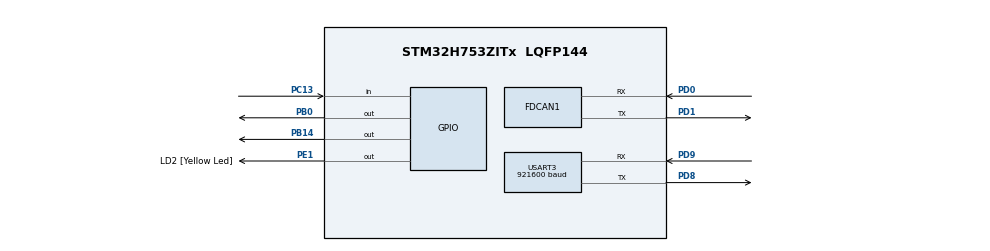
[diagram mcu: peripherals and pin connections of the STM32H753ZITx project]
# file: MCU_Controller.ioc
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CORTEX_M7.CPU_DCache=Disabled
CORTEX_M7.CPU_ICache=Disabled
CORTEX_M7.MPU_Control=MPU_PRIVILEGED_DEFAULT
CORTEX_M7.default_mode_Activation=1
Dma.Request0=USART3_RX
Dma.Request1=USART3_TX
Dma.USART3_RX.0.Direction=DMA_PERIPH_TO_MEMORY
Dma.USART3_RX.0.EventEnable=DISABLE
Dma.USART3_RX.0.FIFOMode=DMA_FIFOMODE_DISABLE
Dma.USART3_RX.0.Instance=DMA1_Stream0
Dma.USART3_RX.0.MemDataAlignment=DMA_MDATAALIGN_BYTE
Dma.USART3_RX.0.MemInc=DMA_MINC_ENABLE
Dma.USART3_RX.0.Mode=DMA_NORMAL
Dma.USART3_RX.0.PeriphDataAlignment=DMA_PDATAALIGN_BYTE
Dma.USART3_RX.0.PeriphInc=DMA_PINC_DISABLE
Dma.USART3_RX.0.Polarity=HAL_DMAMUX_REQ_GEN_RISING
Dma.USART3_RX.0.Priority=DMA_PRIORITY_LOW
Dma.USART3_RX.0.RequestNumber=1
Dma.USART3_RX.0.SignalID=NONE
Dma.USART3_RX.0.SyncEnable=DISABLE
Dma.USART3_RX.0.SyncPolarity=HAL_DMAMUX_SYNC_NO_EVENT
Dma.USART3_RX.0.SyncRequestNumber=1
Dma.USART3_RX.0.SyncSignalID=NONE
Dma.USART3_TX.1.Direction=DMA_MEMORY_TO_PERIPH
Dma.USART3_TX.1.EventEnable=DISABLE
Dma.USART3_TX.1.FIFOMode=DMA_FIFOMODE_DISABLE
Dma.USART3_TX.1.Instance=DMA1_Stream1
Dma.USART3_TX.1.MemDataAlignment=DMA_MDATAALIGN_BYTE
Dma.USART3_TX.1.MemInc=DMA_MINC_ENABLE
Dma.USART3_TX.1.Mode=DMA_NORMAL
Dma.USART3_TX.1.PeriphDataAlignment=DMA_PDATAALIGN_BYTE
Dma.USART3_TX.1.PeriphInc=DMA_PINC_DISABLE
Dma.USART3_TX.1.Polarity=HAL_DMAMUX_REQ_GEN_RISING
Dma.USART3_TX.1.Priority=DMA_PRIORITY_LOW
Dma.USART3_TX.1.RequestNumber=1
Dma.USART3_TX.1.SignalID=NONE
Dma.USART3_TX.1.SyncEnable=DISABLE
Dma.USART3_TX.1.SyncPolarity=HAL_DMAMUX_SYNC_NO_EVENT
Dma.USART3_TX.1.SyncRequestNumber=1
Dma.USART3_TX.1.SyncSignalID=NONE
FDCAN1.AutoRetransmission=ENABLE
FDCAN1.CalculateBaudRateNominal=1000000
FDCAN1.CalculateTimeBitNominal=1000
FDCAN1.CalculateTimeQuantumNominal=25.0
FDCAN1.DataSyncJumpWidth=4
FDCAN1.DataTimeSeg1=5
FDCAN1.DataTimeSeg2=4
FDCAN1.NominalPrescaler=1
FDCAN1.NominalSyncJumpWidth=8
FDCAN1.NominalTimeSeg1=31
FDCAN1.NominalTimeSeg2=8
FDCAN1.RxBuffersNbr=4
FDCAN1.RxFifo0ElmtsNbr=64
FDCAN1.TxBuffersNbr=16
FDCAN1.TxEventsNbr=16
FDCAN1.TxFifoQueueElmtsNbr=32
FDCAN1.TxFifoQueueMode=FDCAN_TX_FIFO_OPERATION
FREERTOS.Tasks01=Control,40,1024,ControlTask,Default,NULL,Dynamic,NULL,NULL;DataLogging,8,2048,DataLoggingTask,Default,NULL,Dynamic,NULL,NULL
FREERTOS.configQUEUE_REGISTRY_SIZE=8
FREERTOS.configTICK_RATE_HZ=500
FREERTOS.configUSE_NEWLIB_REENTRANT=1
Mcu.Family=STM32H7
Mcu.Name=STM32H753ZITx
Mcu.Package=LQFP144
NUCLEO-H753ZI.BUTTON=1
NUCLEO-H753ZI.LD1=true
NUCLEO-H753ZI.LD2=true
NUCLEO-H753ZI.LD3=true
NUCLEO-H753ZI.VCP=false
NVIC.DMA1_Stream0_IRQn=true\:8\:0\:true\:false\:true\:true\:false\:true\:true
NVIC.DMA1_Stream1_IRQn=true\:8\:0\:true\:false\:true\:true\:false\:true\:true
NVIC.EXTI15_10_IRQn=true\:5\:0\:false\:false\:true\:true\:false\:true\:true
NVIC.FDCAN1_IT0_IRQn=true\:6\:0\:true\:false\:true\:true\:true\:true\:true
NVIC.FDCAN1_IT1_IRQn=true\:6\:0\:true\:false\:true\:true\:true\:true\:true
NVIC.PriorityGroup=NVIC_PRIORITYGROUP_4
NVIC.TIM7_IRQn=true\:15\:0\:false\:false\:true\:false\:false\:true\:true
NVIC.TimeBase=TIM7_IRQn
NVIC.TimeBaseIP=TIM7
NVIC.USART3_IRQn=true\:8\:0\:true\:false\:true\:true\:true\:true\:true
PA13\ (JTMS/SWDIO).Signal=DEBUG_JTMS-SWDIO
PA14\ (JTCK/SWCLK).Signal=DEBUG_JTCK-SWCLK
PB0.Signal=GPIO_Output
PB14.Signal=GPIO_Output
PC13.Signal=GPIO_Input
PC14-OSC32_IN\ (OSC32_IN).Signal=RCC_OSC32_IN
PC15-OSC32_OUT\ (OSC32_OUT).Signal=RCC_OSC32_OUT
PD0.GPIO_Speed=GPIO_SPEED_FREQ_HIGH
PD0.Mode=FDCAN_Activate
PD0.Signal=FDCAN1_RX
PD1.GPIO_Speed=GPIO_SPEED_FREQ_HIGH
PD1.Mode=FDCAN_Activate
PD1.Signal=FDCAN1_TX
PD8.Mode=Asynchronous
PD8.Signal=USART3_TX
PD9.Mode=Asynchronous
PD9.Signal=USART3_RX
PE1.GPIO_Label=LD2 [Yellow Led]
PE1.Signal=GPIO_Output
PH0-OSC_IN\ (PH0).Mode=HSE-External-Oscillator
PH0-OSC_IN\ (PH0).Signal=RCC_OSC_IN
PH1-OSC_OUT\ (PH1).Mode=HSE-External-Oscillator
PH1-OSC_OUT\ (PH1).Signal=RCC_OSC_OUT
ProjectManager.HeapSize=0x200
ProjectManager.StackSize=0x400
ProjectManager.TargetToolchain=STM32CubeIDE
RCC.ADCFreq_Value=400000000
RCC.APB1Freq_Value=100000000
RCC.APB2Freq_Value=100000000
RCC.APB3Freq_Value=100000000
RCC.APB4Freq_Value=100000000
RCC.CortexFreq_Value=400000000
RCC.D1PPRE=RCC_APB3_DIV2
RCC.D2PPRE1=RCC_APB1_DIV2
RCC.D2PPRE2=RCC_APB2_DIV2
RCC.D3PPRE=RCC_APB4_DIV2
RCC.DIVM1=1
RCC.DIVM2=1
RCC.DIVN1=100
RCC.DIVN2=100
RCC.DIVQ1=16
RCC.DIVQ2=20
RCC.FDCANCLockSelection=RCC_FDCANCLKSOURCE_PLL2
RCC.HCLKFreq_Value=200000000
RCC.HPRE=RCC_HCLK_DIV2
RCC.HSE_VALUE=8000000
RCC.PLLFRACN=0
RCC.PLLSourceVirtual=RCC_PLLSOURCE_HSE
RCC.PWR_Regulator_Voltage_Scale=PWR_REGULATOR_VOLTAGE_SCALE1
RCC.SYSCLKFreq_VALUE=400000000
RCC.SYSCLKSource=RCC_SYSCLKSOURCE_PLLCLK
RCC.USBFreq_Value=50000000
STMicroelectronics.FP-SNS-STAIOTCFT.1.0.0.MathOoLibCcCMSISJjDSPJjInclude=true
STMicroelectronics.FP-SNS-STAIOTCFT.1.0.0.MathOoLibCcCMSISJjDSPJjLib=true
USART3.BaudRate=921600
USART3.FIFOMode=FIFOMODE_ENABLE
USART3.RXFIFOThreshold=RXFIFO_THRESHOLD_HALFFULL
USART3.TXFIFOThreshold=TXFIFO_THRESHOLD_HALFFULL
USART3.VirtualMode-Asynchronous=VM_ASYNC
VP_FREERTOS_VS_CMSIS_V2.Mode=CMSIS_V2
VP_MEMORYMAP_VS_MEMORYMAP.Mode=CurAppReg
VP_NUCLEO-H753ZI_VS_BSP_COMMON.Mode=COMMON
VP_STMicroelectronics.FP-SNS-STAIOTCFT_VS_CMSISJjMathOoLib_1.0.0_1.0.0.Mode=CMSISJjMathOoLib
VP_SYS_VS_tim7.Mode=TIM7
board=NUCLEO-H753ZI

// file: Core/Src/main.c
/* USER CODE BEGIN Header */
/**
  ******************************************************************************
  * @file           : main.c
  * @brief          : Main program body
  ******************************************************************************
  * @attention
  *
  * Copyright (c) 2025 STMicroelectronics.
  * All rights reserved.
  *
  * This software is licensed under terms that can be found in the LICENSE file
  * in the root directory of this software component.
  * If no LICENSE file comes with this software, it is provided AS-IS.
  *
  ******************************************************************************
  */
/* USER CODE END Header */
#include "main.h"
#include "cmsis_os.h"

/* USER CODE BEGIN Includes */
#include <stdio.h>
#include "FreeRTOS.h"	// Real Time task 세팅을 위해 사용
#include "arm_math.h"	// 선형 대수 연산을 위해 사용
#include "queue.h"		// CAN 통신 수신을 위해 사용
#include "task.h"		// Real Time task 세팅을 위해 사용
#include <string.h>
#include <stdlib.h>   // strtof
#include <errno.h>
#include <stdbool.h>
/* USER CODE END Includes */

/* USER CODE BEGIN PTD */
FDCAN_TxHeaderTypeDef TxHeader;
FDCAN_RxHeaderTypeDef RxHeader;
/* USER CODE END PTD */

FDCAN_HandleTypeDef hfdcan1;

UART_HandleTypeDef huart3;
DMA_HandleTypeDef hdma_usart3_rx;
DMA_HandleTypeDef hdma_usart3_tx;

/* Definitions for Control */
osThreadId_t ControlHandle;
const osThreadAttr_t Control_attributes = {
  .name = "Control",
  .stack_size = 1024 * 4,
  .priority = (osPriority_t) osPriorityHigh,
};
/* Definitions for DataLogging */
osThreadId_t DataLoggingHandle;
const osThreadAttr_t DataLogging_attributes = {
  .name = "DataLogging",
  .stack_size = 2048 * 4,
  .priority = (osPriority_t) osPriorityLow,
};
/* USER CODE BEGIN PV */
// Setting for CAN communication
uint8_t TxData[8], RxData[8];

// Setting for UART communication
// ==== UART3 RX: DMA + IDLE ====
#define UART3_RX_DMA_SIZE   512   // PC 한 줄이 1KB 넘지 않으면 256~512면 충분
static uint8_t  uart3_rx_dma[UART3_RX_DMA_SIZE];

// ===== UART3 RX 링버퍼 (뮤텍스/FreeRTOS 객체 없이 SPSC) =====
#define UART3_RBUF_SIZE    2048      // 총 수신 버퍼 크기 (2의 거듭제곱 권장)
#define UART3_LINE_MAX     1024      // 한 줄 최대 길이

static uint8_t  uart3_rbuf[UART3_RBUF_SIZE];
static volatile uint16_t uart3_widx = 0;   // ISR가 증가 (writer)
static volatile uint16_t uart3_ridx = 0;   // Task가 증가 (reader)

// 한 줄 조립용 작업버퍼 (Task 전용)
static char    uart3_line[UART3_LINE_MAX];
static size_t  uart3_line_len = 0;

// 수신 메시지 필드 수: [t, x, y, z, xKp, xKi, xKd, xCut, xAw, yKp, yKi, yKd, yCut, yAw, zKp, zKi, zKd, zCut, zAw]
#define PC_MSG_FIELDS 19

// ==== UART3 TX: 비동기 DMA 송신 링버퍼 ====
#define UART3_TBUF_SIZE     4096  // printf 트래픽에 맞게 조정
static uint8_t  uart3_tbuf[UART3_TBUF_SIZE];
static volatile uint16_t uart3_tx_widx = 0;
static volatile uint16_t uart3_tx_ridx = 0;
static volatile uint16_t uart3_tx_last_len = 0;
static volatile uint8_t  uart3_tx_busy = 0;

// Setting for Control
#define NUM_IMUS 3 // IMU 3개
#define NUM_MOTORS 3 // motor 3개
#define NUM_TASK_DEG 3 // task space 자유도 3

const float32_t Ts        = 0.002;			// time interval (sec)
const float32_t pi        = 3.141592;       // 원주율 설정
const float32_t g         = 9.80665;		// gravity acceleration (m/s^2)
uint32_t ctrl_time_ms     = 0;				// current control time (millisec)
uint32_t ctrl_time_ms_old = 0;  			// previous control time (millisec)
uint32_t logging_time_ms  = 0;   			// current logging time (millisec)

// Individual motor control reference
float32_t target_pos[NUM_MOTORS] = {
    0,  // Motor 0: rad
	0,
	0
};
float32_t target_vel[NUM_MOTORS] = {
    0,  // Motor 0: rad/s
	0,
	0
};

// IMU Structure Definition
typedef struct {
	int id;
	QueueHandle_t canRxQueue_accel;  // IMU CAN communication data
	QueueHandle_t canRxQueue_gyro;  // IMU CAN communication data

	float32_t accelX;
	float32_t accelY;
	float32_t accelZ;

	float32_t gyroX;
	float32_t gyroY;
	float32_t gyroZ;
} IMU;

// Motor Structure Definition
typedef struct {
	// motor state definition
	int id;					// motor CAN id
	int current_motor_mode;		// motor enable: 1, disable: 0
	QueueHandle_t canRxQueue;  // motor CAN communication data
	float32_t encoder_pulses;
	float32_t gear_ratio;
	float32_t Kt;
	float32_t sensor_cutoff;
	float32_t pos_ref; 		// motor position reference
	float32_t vel_ref;		    // motor velocity reference
	float32_t pos;				// motor current position
	float32_t pos_old;			// motor 1 step previous position
	float32_t vel;				// motor current velocity
	float32_t vel_old;			// motor 1 step previous velocity
	float32_t acc;				// motor current acceleration
	float32_t acc_old;			// motor 1 step previous acceleration
	float32_t pos_error;		// motor current position error
	float32_t pos_error_old;	// motor 1 step previous position error
	float32_t pos_P_term;
	float32_t pos_I_term; // motor current accumulate error
	float32_t pos_I_term_old; // motor 1 step previous accumulate error
	float32_t pos_D_term; // motor current derivative error
	float32_t pos_D_term_old; // motor 1 step previous derivative error
	float32_t vel_error;		// motor current velocity error
	float32_t vel_error_old;   // motor 1 step previous velocity error
	float32_t vel_P_term;
	float32_t vel_I_term;  // motor current derivative error
	float32_t vel_I_term_old; // motor 1 step previous derivative error
	// motor pid gain setting
	float32_t pos_kp;
	float32_t pos_kd;
	float32_t cutoff_pos_pid;
	float32_t pos_ki;
	float32_t vel_kp;
	float32_t vel_ki;
	// motor control input
	float32_t control_input;
	float32_t control_input_old;
	// motor current limit
	float32_t upper_CL;
	float32_t lower_CL;
	// motor saturated term
	float32_t control_input_excess;
} Motor;

// robot control reference
float32_t homing_q_bi_buffer[NUM_MOTORS] = {
    0 * (pi/180),  		// q1: rad
	60 * (pi/180),  	// qm: rad
	- 60 * (pi/180),  	// qb: rad
};
arm_matrix_instance_f32 homing_q_bi;

float32_t homing_posXYZ_buffer[NUM_TASK_DEG] = {
    0.46,  	// x: m
	0,  	// y: m
	0.176   // z: m
};
arm_matrix_instance_f32 homing_posXYZ;

float32_t taskTime = 1.0f;
float32_t desired_posXYZ[NUM_TASK_DEG] = {
	0.46,  	// x: m
	0,  	// y: m
	0.176   // z: m
};

float32_t target_posXYZ_buffer[NUM_TASK_DEG] = {
    0.46,  	// x: m
	0,  	// y: m
	0.176   // z: m
};
arm_matrix_instance_f32 target_posXYZ;

// robot control gains
float32_t taskspace_p_gain[NUM_TASK_DEG]      = {0, 0, 0}; // 180
float32_t taskspace_i_gain[NUM_TASK_DEG]      = {0, 0, 0};    // 30
float32_t taskspace_d_gain[NUM_TASK_DEG]      = {0, 0, 0};       // 3
float32_t taskspace_windup_gain[NUM_TASK_DEG] = {0, 0, 0};       // 0
float32_t taskspace_pid_cutoff[NUM_TASK_DEG]  = {150, 150, 150}; // 150

// Manipulator Structure Definition
typedef struct {
	// manipulator safety state definition
	int current_robot_mode;		// robot enable: 1, disable: 0
	int desired_robot_mode;

	// IMU structure definition
	IMU IMUs[NUM_IMUS];

	// Motor structure definition
	Motor motors[NUM_MOTORS];

	// manipulator joint state definition
	float32_t axis_configuration[NUM_MOTORS]; // 모터 축 방향 설정
	arm_matrix_instance_f32 q;
	float32_t q_buffer[NUM_MOTORS];
	float32_t q_upper_ROM[NUM_MOTORS];
	float32_t q_lower_ROM[NUM_MOTORS];
	arm_matrix_instance_f32 q_bi;
	float32_t q_bi_buffer[NUM_MOTORS];
	arm_matrix_instance_f32 q_bi_old;
	float32_t q_bi_old_buffer[NUM_MOTORS];
	arm_matrix_instance_f32 qdot_bi;
	float32_t qdot_bi_buffer[NUM_MOTORS];
	arm_matrix_instance_f32 qdot_bi_old;
	float32_t qdot_bi_old_buffer[NUM_MOTORS];
	arm_matrix_instance_f32 qddot_bi;
	float32_t qddot_bi_buffer[NUM_MOTORS];
	arm_matrix_instance_f32 qddot_bi_old;
	float32_t qddot_bi_old_buffer[NUM_MOTORS];

	// manipulator taskspace state definition
	arm_matrix_instance_f32 posXYZ_ref;
	float32_t posXYZ_ref_buffer[NUM_TASK_DEG];
	arm_matrix_instance_f32 posXYZ_ref_old;
	float32_t posXYZ_ref_old_buffer[NUM_TASK_DEG];
	arm_matrix_instance_f32 posXYZ;
	float32_t posXYZ_buffer[NUM_TASK_DEG];
	arm_matrix_instance_f32 posXYZ_old;
	float32_t posXYZ_old_buffer[NUM_TASK_DEG];
	arm_matrix_instance_f32 velXYZ;
	float32_t velXYZ_buffer[NUM_TASK_DEG];
	arm_matrix_instance_f32 velXYZ_old;
	float32_t velXYZ_old_buffer[NUM_TASK_DEG];
	arm_matrix_instance_f32 accXYZ;
	float32_t accXYZ_buffer[NUM_TASK_DEG];
	arm_matrix_instance_f32 accXYZ_old;
	float32_t accXYZ_old_buffer[NUM_TASK_DEG];

	// manipulator model params definition
	float32_t m1, m2, m3;
	float32_t l1, l2, l3;
	float32_t J1, J2, J3;
	float32_t d2, d3;
	arm_matrix_instance_f32 jacb_bi;
	float32_t jacb_bi_buffer[NUM_TASK_DEG * NUM_MOTORS];
	arm_matrix_instance_f32 jacb_bi_inv;
	float32_t jacb_bi_inv_buffer[NUM_TASK_DEG * NUM_MOTORS];
	arm_matrix_instance_f32 jacb_bi_trans;
	float32_t jacb_bi_trans_buffer[NUM_TASK_DEG * NUM_MOTORS];
	arm_matrix_instance_f32 jacb_bi_trans_inv;
	float32_t jacb_bi_trans_inv_buffer[NUM_TASK_DEG * NUM_MOTORS];
	arm_matrix_instance_f32 M_bi;
	float32_t M_bi_buffer[NUM_MOTORS * NUM_MOTORS];
	arm_matrix_instance_f32 C_bi;
	float32_t C_bi_buffer[NUM_MOTORS];
	arm_matrix_instance_f32 G_bi;
	float32_t G_bi_buffer[NUM_MOTORS];
	arm_matrix_instance_f32 M_bi_task;
	float32_t M_bi_task_buffer[NUM_TASK_DEG * NUM_TASK_DEG];
	arm_matrix_instance_f32 M_bi_task_nominal;
	float32_t M_bi_task_nominal_buffer[NUM_TASK_DEG * NUM_TASK_DEG];

	// manipulator pd gain setting
	float32_t pos_kp[NUM_TASK_DEG];
	float32_t pos_ki[NUM_TASK_DEG];
	float32_t pos_kd[NUM_TASK_DEG];
	float32_t pos_k_windup[NUM_TASK_DEG];
	float32_t cutoff_pos_pid[NUM_TASK_DEG];

	// manipulator task space pid control state definition
	arm_matrix_instance_f32 pos_error;
	float32_t pos_error_buffer[NUM_TASK_DEG];
	arm_matrix_instance_f32 pos_error_old;
	float32_t pos_error_old_buffer[NUM_TASK_DEG];
	arm_matrix_instance_f32 pos_P_term;
	float32_t pos_P_term_buffer[NUM_TASK_DEG];
	arm_matrix_instance_f32 pos_I_term;
	float32_t pos_I_term_buffer[NUM_TASK_DEG];
	arm_matrix_instance_f32 pos_I_term_old;
	float32_t pos_I_term_old_buffer[NUM_TASK_DEG];
	arm_matrix_instance_f32 pos_D_term;
	float32_t pos_D_term_buffer[NUM_TASK_DEG];
	arm_matrix_instance_f32 pos_D_term_old;
	float32_t pos_D_term_old_buffer[NUM_TASK_DEG];
	arm_matrix_instance_f32 pos_pid_output;
	float32_t pos_pid_output_buffer[NUM_TASK_DEG];

	// manipulator task space DOB control state definition
	float32_t cut_off_DOB[NUM_MOTORS];
	arm_matrix_instance_f32 DOB_lhs;
	float32_t DOB_lhs_buffer[NUM_MOTORS];
	arm_matrix_instance_f32 DOB_lhs_old;
	float32_t DOB_lhs_old_buffer[NUM_MOTORS];
	arm_matrix_instance_f32 DOB_filtered_lhs;
	float32_t DOB_filtered_lhs_buffer[NUM_MOTORS];
	arm_matrix_instance_f32 DOB_filtered_lhs_old;
	float32_t DOB_filtered_lhs_old_buffer[NUM_MOTORS];
	arm_matrix_instance_f32 DOB_rhs;
	float32_t DOB_rhs_buffer[NUM_MOTORS];
	arm_matrix_instance_f32 DOB_rhs_old;
	float32_t DOB_rhs_old_buffer[NUM_MOTORS];
	arm_matrix_instance_f32 DOB_filtered_rhs;
	float32_t DOB_filtered_rhs_buffer[NUM_MOTORS];
	arm_matrix_instance_f32 DOB_filtered_rhs_old;
	float32_t DOB_filtered_rhs_old_buffer[NUM_MOTORS];

	// manipulator control input
	arm_matrix_instance_f32 tau_bi;
	float32_t tau_bi_buffer[NUM_MOTORS];
	arm_matrix_instance_f32 tau_bi_old;
	float32_t tau_bi_old_buffer[NUM_MOTORS];
	arm_matrix_instance_f32 tau_bi_excess;
	float32_t tau_bi_excess_buffer[NUM_MOTORS];
	arm_matrix_instance_f32 pos_pid_output_excess;
	float32_t pos_pid_output_excess_buffer[NUM_TASK_DEG];
	arm_matrix_instance_f32 pos_pid_output_excess_old;
	float32_t pos_pid_output_excess_old_buffer[NUM_TASK_DEG];
} Manipulator;

Manipulator strawberry_robot;

// Quintic Trajectory Structure Definition
typedef struct {
	float32_t task_time;
	float32_t initial_time;
	float32_t final_time;

	float32_t initial_pos[3];
	float32_t initial_vel[3];
	float32_t initial_acc[3];
	float32_t final_pos[3];
	float32_t final_vel[3];
	float32_t final_acc[3];

	float32_t xpos_coefficient[6];
	float32_t ypos_coefficient[6];
	float32_t zpos_coefficient[6];
} Trajectory;

Trajectory quintic_traj;

// Setting for Debug
int sta = 0;
/* USER CODE END PV */

void SystemClock_Config(void);
static void MPU_Config(void);
static void MX_GPIO_Init(void);
static void MX_DMA_Init(void);
static void MX_FDCAN1_Init(void);
static void MX_USART3_UART_Init(void);
void ControlTask(void *argument);
void DataLoggingTask(void *argument);

/* USER CODE BEGIN 0 */
// Console Display Functions ----------------------------------------------------
// 링버퍼에 len 바이트 밀어넣기 (꽉 차면 오래된 것부터 드롭)
static void uart3_rb_push_bytes(const uint8_t *src, uint16_t len)
{
  if (len == 0) return;

  uint16_t w = uart3_widx;
  uint16_t r = uart3_ridx;

  // 남은 공간 계산 (1바이트 비워두는 구조)
  uint16_t free = (r > w) ? (r - w - 1) : (UART3_RBUF_SIZE - (w - r) - 1);
  if (len > free) {
    uint16_t drop = len - free;
    uart3_ridx = (uart3_ridx + drop) & (UART3_RBUF_SIZE - 1);
  }

  // 연속 구간으로 두 번에 나눠 복사
  uint16_t to_end = UART3_RBUF_SIZE - w;
  uint16_t first  = (len < to_end) ? len : to_end;
  memcpy(&uart3_rbuf[w], src, first);
  if (len > first) memcpy(&uart3_rbuf[0], src + first, len - first);

  uart3_widx = (w + len) & (UART3_RBUF_SIZE - 1);
}

// NORMAL 모드 + IDLE 이벤트 기반 재무장 (레지스터 직접접근 X)
static void uart3_rx_start_normal(void)
{
  // 1) RX DMA가 CIRC로 잡혀 있다면 HAL로 NORMAL로 재초기화
  if (huart3.hdmarx) {
    if (huart3.hdmarx->Init.Mode != DMA_NORMAL) {
      // 안전하게 모두 중단
      HAL_UART_AbortReceive(&huart3);
      HAL_DMA_Abort(huart3.hdmarx);

      // DMA를 NORMAL로 재설정
      HAL_DMA_DeInit(huart3.hdmarx);
      huart3.hdmarx->Init.Mode = DMA_NORMAL;
      if (HAL_DMA_Init(huart3.hdmarx) != HAL_OK) {
        sta = 3;  // MCU Init 에러 코드 재사용
        Error_Handler();
      }
      // __HAL_LINKDMA(&huart3, hdmarx, *huart3.hdmarx); // 보통 재링크 불필요
    }
    // Half-Transfer IRQ는 사용 안 함
    __HAL_DMA_DISABLE_IT(huart3.hdmarx, DMA_IT_HT);
  }

  // 2) IDLE 플래그 정리하고 ToIdle-DMA 재무장
  __HAL_UART_CLEAR_IDLEFLAG(&huart3);
  if (HAL_UARTEx_ReceiveToIdle_DMA(&huart3, uart3_rx_dma, UART3_RX_DMA_SIZE) != HAL_OK) {
    sta = 3;
    Error_Handler();
  }
}

// ToIdle-DMA가 IDLE 또는 버퍼가 다 찼을 때 호출됨 (Size: 수신 바이트 수)
void HAL_UARTEx_RxEventCallback(UART_HandleTypeDef *huart, uint16_t Size)
{
  if (huart->Instance != USART3) return;

  if (Size) {
    uart3_rb_push_bytes(uart3_rx_dma, Size);
  }
  // 다음 수신 다시 무장
  uart3_rx_start_normal();
}

// 혹시 HAL이 TC로만 불러줄 수도 있으므로 안전망 콜백도 구현
void HAL_UART_RxCpltCallback(UART_HandleTypeDef *huart)
{
  if (huart->Instance != USART3) return;

  uart3_rb_push_bytes(uart3_rx_dma, UART3_RX_DMA_SIZE);
  uart3_rx_start_normal();
}

// 에러 시 플래그 정리하고 즉시 재무장
void HAL_UART_ErrorCallback(UART_HandleTypeDef *huart)
{
  if (huart->Instance != USART3) return;

  HAL_UART_AbortReceive(huart);

  __HAL_UART_CLEAR_OREFLAG(huart);
  __HAL_UART_CLEAR_FEFLAG(huart);
  __HAL_UART_CLEAR_NEFLAG(huart);
  __HAL_UART_CLEAR_PEFLAG(huart);
  __HAL_UART_CLEAR_IDLEFLAG(huart);

  uart3_rx_start_normal();
}

static void uart3_kick_tx_dma(void)
{
  if (uart3_tx_busy) return;
  if (uart3_tx_ridx == uart3_tx_widx) return; // empty

  // 연속 구간 길이 산출 (wrap 안 끊기게 1번 전송)
  uint16_t len = (uart3_tx_widx >= uart3_tx_ridx)
               ? (uart3_tx_widx - uart3_tx_ridx)
               : (UART3_TBUF_SIZE - uart3_tx_ridx);

  uart3_tx_last_len = len;
  uart3_tx_busy = 1;

  // (D-Cache 켠 경우) DMA가 읽을 영역 클린
  // SCB_CleanDCache_by_Addr((uint32_t*)&uart3_tbuf[uart3_tx_ridx], len);

  HAL_UART_Transmit_DMA(&huart3, &uart3_tbuf[uart3_tx_ridx], len);
}

void HAL_UART_TxCpltCallback(UART_HandleTypeDef *huart)
{
  if (huart->Instance != USART3) return;

  uart3_tx_ridx = (uart3_tx_ridx + uart3_tx_last_len) & (UART3_TBUF_SIZE - 1);
  uart3_tx_busy = 0;
  uart3_kick_tx_dma(); // 남은 데이터가 있으면 곧장 다음 덩어리 전송
}

static size_t uart3_tx_write(const uint8_t *data, size_t len)
{
  size_t w = 0;
  while (w < len) {
    // 먼저 남은 공간 계산(논크리티컬)
    uint16_t r = uart3_tx_ridx;
    uint16_t w0 = uart3_tx_widx;
    uint16_t space = (r > w0) ? (r - w0 - 1) : (UART3_TBUF_SIZE - (w0 - r) - 1);
    if (space == 0) break;

    size_t chunk = (len - w < space) ? (len - w) : space;
    size_t first = (w0 + chunk <= UART3_TBUF_SIZE) ? chunk : (UART3_TBUF_SIZE - w0);

    memcpy(&uart3_tbuf[w0], &data[w], first);
    if (chunk > first) memcpy(&uart3_tbuf[0], &data[w + first], chunk - first);

    taskENTER_CRITICAL();
    uart3_tx_widx = (w0 + chunk) & (UART3_TBUF_SIZE - 1);
    uart3_kick_tx_dma();
    taskEXIT_CRITICAL();

    w += chunk;
  }
  return w;
}

int _write(int file, char *p, int len)
{
  size_t pos = 0;
  while (pos < (size_t)len) {
    size_t n = uart3_tx_write((uint8_t*)p + pos, (size_t)len - pos);
    if (n == 0) {
      // 버퍼가 가득 → RT 제어를 막지 않게 즉시 양보
      if (xTaskGetSchedulerState() == taskSCHEDULER_RUNNING) {
        taskYIELD();      // 또는 vTaskDelay(1) 등
      } else {
        // 스케줄러 전이면 잠깐 회전
      }
    } else {
      pos += n;
    }
  }
  return len;
}

// 링버퍼에서 1바이트 pop (읽을 게 없으면 0 반환)
static int uart3_rb_pop(uint8_t *out)
{
  if (uart3_ridx == uart3_widx) return 0;  // empty
  *out = uart3_rbuf[uart3_ridx];
  uart3_ridx = (uart3_ridx + 1) & (UART3_RBUF_SIZE - 1);
  return 1;
}

// 좌우 공백 제거
static inline void trim_spaces(char *s) {
  char *p = s;
  while (*p==' ' || *p=='\t') ++p;
  if (p!=s) memmove(s, p, strlen(p)+1);
  for (int i=(int)strlen(s)-1; i>=0 && (s[i]==' ' || s[i]=='\t'); --i) s[i]='\0';
}

// 한 줄을 파싱: [ ... 19개 ... ] 에서 float들 추출
static int parse_pc_line_to_floats(char *line, float vals[], int maxn)
{
  char *L = strchr(line, '[');
  char *R = strrchr(line, ']');
  if (!L || !R || R <= L) return 0;

  *R = '\0'; ++L;

  int count = 0;
  char *p = L;

  while (*p && count < maxn) {
    // 구분자(,) 전까지 토큰 범위 찾기
    char *q = p;
    while (*q && *q != ',') ++q;

    // 토큰 문자열 [p, q)
    // 앞뒤 공백 제거
    while (*p == ' ' || *p == '\t') ++p;
    char *e = q;
    while (e > p && (e[-1] == ' ' || e[-1] == '\t')) --e;

    if (e > p) { // 빈 토큰이 아니면
      errno = 0;
      char tmp = *e; *e = '\0';
      char *endptr = NULL;
      float v = strtof(p, endptr ? &endptr : &e); // newlib-nano 대응
      if (endptr) {
        while (*endptr == ' ' || *endptr == '\t') ++endptr;
        if (errno != 0 || *endptr != '\0') return 0; // 유효 숫자 아님 → 실패
      }
      vals[count++] = v;
      *e = tmp;
    }
    // 끝 처리
    if (*q == '\0') break;
    p = q + 1;
  }

  // 꼭 19개여야 성공
  return (count == PC_MSG_FIELDS) ? count : 0;
}

// 파싱 결과를 시스템 파라미터에 반영 (요청대로 DataLoggingTask에서 직접 반영)
static void apply_pc_floats(const float v[PC_MSG_FIELDS])
{
	// 인덱스 매핑
	const int T   = 0;
	const int tx  = 1,  ty  = 2,  tz  = 3;
	const int xKp = 4,  xKi = 5,  xKd = 6,  xCf = 7,  xAw = 8;
	const int yKp = 9,  yKi =10,  yKd =11,  yCf =12,  yAw =13;
	const int zKp =14,  zKi =15,  zKd =16,  zCf =17,  zAw =18;

	// 간단한 유효성 (원하면 강화)
	if (v[xCf] <= 0 || v[yCf] <= 0 || v[zCf] <= 0) return;

	// 1) taskTime & 타겟 위치 설정
	taskTime = v[T];
	desired_posXYZ[0] = v[tx];
	desired_posXYZ[1] = v[ty];
	desired_posXYZ[2] = v[tz];

	// 3) XYZ 게인/컷오프/안티윈드업
	taskspace_p_gain[0]     	   = v[xKp];
	taskspace_i_gain[0]     	   = v[xKi];
	taskspace_d_gain[0]     	   = v[xKd];
	taskspace_pid_cutoff[0]        = v[xCf];
	taskspace_windup_gain[0]       = v[xAw];

	taskspace_p_gain[1]     	   = v[yKp];
	taskspace_i_gain[1]     	   = v[yKi];
	taskspace_d_gain[1]     	   = v[yKd];
	taskspace_pid_cutoff[1]        = v[yCf];
	taskspace_windup_gain[1]       = v[yAw];

	taskspace_p_gain[2]     	   = v[zKp];
	taskspace_i_gain[2]    	       = v[zKi];
	taskspace_d_gain[2]     	   = v[zKd];
	taskspace_pid_cutoff[2]        = v[zCf];
	taskspace_windup_gain[2]       = v[zAw];
}

// 링버퍼에서 줄 단위로 꺼내 처리 (CR 무시, LF로 완료)
static void uart3_poll_and_process_lines(void)
{
  uint8_t b;
  while (uart3_rb_pop(&b)) {
    char c = (char)b;
    if (c == '\r') continue;

    if (c == '\n') {
      if (uart3_line_len > 0) {
        uart3_line[uart3_line_len] = '\0';

        float vals[PC_MSG_FIELDS];
        int n = parse_pc_line_to_floats(uart3_line, vals, PC_MSG_FIELDS);
        if (n >= PC_MSG_FIELDS) {
          apply_pc_floats(vals);
        } else {
          // 형식 불일치 시 무시(필요하면 printf로 경고)
          // printf("UART parse fail: got %d fields\r\n", n);
        }
        uart3_line_len = 0;
      }
    } else {
      if (uart3_line_len < UART3_LINE_MAX - 1) {
        uart3_line[uart3_line_len++] = c;
      } else {
        // 라인 과길이 → 드롭 & 리셋
        uart3_line_len = 0;
      }
    }
  }
}

// Safety Button Functions ----------------------------------------------------
void HAL_GPIO_EXTI_Callback(uint16_t GPIO_Pin)
{
	if (strawberry_robot.current_robot_mode == 0)
	{
		strawberry_robot.desired_robot_mode = 1;
	}
	else
	{
		strawberry_robot.desired_robot_mode = 0;
	}
}

void BSP_PB_Callback(Button_TypeDef Button)
{
    if (Button == BUTTON_USER)
    {
        HAL_GPIO_EXTI_Callback(GPIO_PIN_13);  // 내부 콜백 호출 강제 연결
    }
}

// CAN Communication Functions ----------------------------------------------------
int float32_t_to_uint(float32_t x, float32_t x_min, float32_t x_max, unsigned int bits)
{
	// Converts a float to an unsigned int, given range and number of bits
    float32_t span = x_max - x_min;
    if (x < x_min) x = x_min;
    else if (x > x_max) x = x_max;

    return (unsigned int)((x - x_min) * ((float32_t)((1ULL << bits) - 1) / span));
}

float32_t uint_to_float32_t(unsigned int x_int, float32_t x_min, float32_t x_max, unsigned int bits)
{
	// converts unsigned int to float, given range and number of bits
    float32_t span = x_max - x_min;
    float32_t offset = x_min;

    return ((float32_t)x_int) * span / ((float32_t)((1ULL << bits) - 1)) + offset;
}

void MIT_reset_origin(const uint16_t motor_id){
	uint8_t buffer[8];   // transmit buffer

	buffer[0]=0xff;
	buffer[1]=0xff;
	buffer[2]=0xff;
	buffer[3]=0xff;
	buffer[4]=0xff;
	buffer[5]=0xff;
	buffer[6]=0xff;
	buffer[7]=0xfe;

	TxHeader.Identifier = motor_id;
	TxHeader.IdType = FDCAN_STANDARD_ID;
	TxHeader.TxFrameType = FDCAN_DATA_FRAME;
	TxHeader.DataLength = FDCAN_DLC_BYTES_8;
	TxHeader.ErrorStateIndicator = FDCAN_ESI_ACTIVE;
	TxHeader.BitRateSwitch = FDCAN_BRS_OFF;
	TxHeader.FDFormat = FDCAN_CLASSIC_CAN;
	TxHeader.MessageMarker = 0;
	TxHeader.TxEventFifoControl = FDCAN_NO_TX_EVENTS;

	if (HAL_FDCAN_AddMessageToTxFifoQ(&hfdcan1, &TxHeader, buffer) != HAL_OK) {
		sta = 1;
		Error_Handler();
	}
}

void MIT_enter_control_mode(const uint16_t motor_id){
	uint8_t buffer[8]; // motor control buffer

	buffer[0]=0xff;
	buffer[1]=0xff;
	buffer[2]=0xff;
	buffer[3]=0xff;
	buffer[4]=0xff;
	buffer[5]=0xff;
	buffer[6]=0xff;
	buffer[7]=0xfc;

	TxHeader.Identifier = motor_id;
	TxHeader.IdType = FDCAN_STANDARD_ID;
	TxHeader.TxFrameType = FDCAN_DATA_FRAME;
	TxHeader.DataLength = FDCAN_DLC_BYTES_8;
	TxHeader.ErrorStateIndicator = FDCAN_ESI_ACTIVE;
	TxHeader.BitRateSwitch = FDCAN_BRS_OFF;
	TxHeader.FDFormat = FDCAN_CLASSIC_CAN;
	TxHeader.MessageMarker = 0;
	TxHeader.TxEventFifoControl = FDCAN_NO_TX_EVENTS;

	if (HAL_FDCAN_AddMessageToTxFifoQ(&hfdcan1, &TxHeader, buffer) != HAL_OK) {
		sta = 1;
		Error_Handler();
	}
}

void MIT_exit_control_mode(const uint16_t motor_id){
	uint8_t buffer[8]; // motor control buffer

	buffer[0]=0xff;
	buffer[1]=0xff;
	buffer[2]=0xff;
	buffer[3]=0xff;
	buffer[4]=0xff;
	buffer[5]=0xff;
	buffer[6]=0xff;
	buffer[7]=0xfd;

	TxHeader.Identifier = motor_id;
	TxHeader.IdType = FDCAN_STANDARD_ID;
	TxHeader.TxFrameType = FDCAN_DATA_FRAME;
	TxHeader.DataLength = FDCAN_DLC_BYTES_8;
	TxHeader.ErrorStateIndicator = FDCAN_ESI_ACTIVE;
	TxHeader.BitRateSwitch = FDCAN_BRS_OFF;
	TxHeader.FDFormat = FDCAN_CLASSIC_CAN;
	TxHeader.MessageMarker = 0;
	TxHeader.TxEventFifoControl = FDCAN_NO_TX_EVENTS;

	if (HAL_FDCAN_AddMessageToTxFifoQ(&hfdcan1, &TxHeader, buffer) != HAL_OK) {
		sta = 1;
		Error_Handler();
	}
}

void MIT_TxData(uint8_t* buffer, int16_t number) {
	buffer[0] = 0;
	buffer[1] = 0;
	buffer[2] = 0;
	buffer[3] = 0;
	buffer[4] = 0;
	buffer[5] = 0;
	buffer[6] =(number&0x0f00) >> 8;
	buffer[7] = number&0x00ff;
}

void MIT_Mode(const uint16_t motor_id, float current_ref){
	uint8_t buffer[8];
	const float32_t I_MIN = -25.0f;
	const float32_t I_MAX = 25.0f;
	current_ref = fmin(fmax(I_MIN, current_ref), I_MAX);
	int i_int = float32_t_to_uint(current_ref, I_MIN, I_MAX, 12);

	MIT_TxData(buffer, (int16_t)(i_int));

	TxHeader.Identifier = motor_id;
	TxHeader.IdType = FDCAN_STANDARD_ID;
	TxHeader.TxFrameType = FDCAN_DATA_FRAME;
	TxHeader.DataLength = FDCAN_DLC_BYTES_8;
	TxHeader.ErrorStateIndicator = FDCAN_ESI_ACTIVE;
	TxHeader.BitRateSwitch = FDCAN_BRS_OFF;
	TxHeader.FDFormat = FDCAN_CLASSIC_CAN;
	TxHeader.MessageMarker = 0;
	TxHeader.TxEventFifoControl = FDCAN_NO_TX_EVENTS;

	if (HAL_FDCAN_AddMessageToTxFifoQ(&hfdcan1, &TxHeader, buffer) != HAL_OK) {
		sta = 1;
		Error_Handler();
	}
}

void HAL_FDCAN_RxFifo0Callback(FDCAN_HandleTypeDef *hfdcan, uint32_t RxFifo0ITs)
{
    if ((RxFifo0ITs & FDCAN_IT_RX_FIFO0_NEW_MESSAGE) != 0)
    {
        FDCAN_RxHeaderTypeDef RxHeader;
        uint8_t RxData[8];

        if (HAL_FDCAN_GetRxMessage(hfdcan, FDCAN_RX_FIFO0, &RxHeader, RxData) != HAL_OK)
        {
            sta = 2;
            Error_Handler();
        }

        uint8_t id = RxHeader.Identifier;

        // 해당 ID와 일치하는 motor 찾기
        for (int i = 0; i < NUM_MOTORS; ++i)
        {
            if (strawberry_robot.motors[i].id == id)
            {
                // 해당 motor의 수신 큐에 RxData[8] 통째로 넣기
                BaseType_t xHigherPriorityTaskWoken = pdFALSE;
                xQueueSendFromISR(strawberry_robot.motors[i].canRxQueue, RxData, &xHigherPriorityTaskWoken);
                portYIELD_FROM_ISR(xHigherPriorityTaskWoken);
                break;
            }
        }
        // 해당 ID와 일치하는 IMU 찾기
        if (RxData[0] == 0xF0) // IMU의 동기화 데이터는 0xF0로 시작함.
        {
        	for (int i = 0; i < NUM_IMUS; ++i)
			{
				if (strawberry_robot.IMUs[i].id == id)
				{
					BaseType_t xHigherPriorityTaskWoken = pdFALSE;
					if (RxData[1] == 0x33) // 받은 데이터가 가속도 값인 경우 (가속도 코드: 0x33)
					{
						// 해당 IMU의 수신 큐에 RxData[8] 통째로 넣기
						xQueueSendFromISR(strawberry_robot.IMUs[i].canRxQueue_accel, RxData, &xHigherPriorityTaskWoken);
					}
					else if (RxData[1] == 0x34) // 받은 데이터가 각속도 값인 경우 (각속도 코드: 0x34)
					{
						// 해당 IMU의 수신 큐에 RxData[8] 통째로 넣기
						xQueueSendFromISR(strawberry_robot.IMUs[i].canRxQueue_gyro, RxData, &xHigherPriorityTaskWoken);
					}
					else
					{
						// 다른 메시지가 전송된 경우 무시
					}
					portYIELD_FROM_ISR(xHigherPriorityTaskWoken);
					break;
				}
			}
        }

        HAL_GPIO_TogglePin(GPIOE, LED2_PIN);  // 수신 표시
    }
}

// Filter Functions ----------------------------------------------------
float32_t tustin_derivative(float32_t input, float32_t input_old, float32_t output_old, float32_t cutoff_freq)
{
    float32_t time_const = 1 / (2 * pi * cutoff_freq);
    float32_t output = 0;

    output = (2 * (input - input_old) - (Ts - 2 * time_const) * output_old) / (Ts + 2 * time_const);

    return output;
}

float32_t tustin_integrate(float32_t input, float32_t input_old, float32_t output_old)
{
  float32_t output = 0;

  output = (Ts * (input + input_old) + 2 * output_old) / 2;

  return output;
}

float32_t lowpassfilter(float32_t input, float32_t input_old, float32_t output_old, float32_t cutoff_freq)
{
    float32_t time_const = 1 / (2 * pi * cutoff_freq);
    float32_t output = 0;

    output = (Ts * (input + input_old) - (Ts - 2 * time_const) * output_old) / (Ts + 2 * time_const);

    return output;
}

// IMU Sensing Functions ----------------------------------------------------
void link_IMU_read(IMU *imu)
{
    uint8_t buf[8], last_acc[8], last_gyr[8];
    int got_acc = 0, got_gyr = 0;
    // 1) 가속도 큐 비우고 마지막 패킷 유지
    while (xQueueReceive(imu->canRxQueue_accel, buf, 0) == pdPASS) {
        memcpy(last_acc, buf, 8);
        got_acc = 1;
    }
    if (got_acc) {
        // 동기화 패킷/인덱스 한번 더 확인: 0xF0 / 0x33
        if (last_acc[0] == 0xF0 && last_acc[1] == 0x33) {
            imu->accelX = (float)((int16_t)((uint16_t)last_acc[2] | ((uint16_t)last_acc[3] << 8))) * 0.001f;
            imu->accelY = (float)((int16_t)((uint16_t)last_acc[4] | ((uint16_t)last_acc[5] << 8))) * 0.001f;
            imu->accelZ = (float)((int16_t)((uint16_t)last_acc[6] | ((uint16_t)last_acc[7] << 8))) * 0.001f;
        }
        else {
            // 필요시: 예외 처리/로그
        }
    }
    // 2) 자이로 큐 비우고 마지막 패킷 유지
    while (xQueueReceive(imu->canRxQueue_gyro, buf, 0) == pdPASS) {
        memcpy(last_gyr, buf, 8);
        got_gyr = 1;
    }
    if (got_gyr) {
        // 동기화 패킷/인덱스 한번 더 확인: 0xF0 / 0x34
        if (last_gyr[0] == 0xF0 && last_gyr[1] == 0x34) {
            imu->gyroX = (float)((int16_t)((uint16_t)last_gyr[2] | ((uint16_t)last_gyr[3] << 8))) * 0.1f;
            imu->gyroY = (float)((int16_t)((uint16_t)last_gyr[4] | ((uint16_t)last_gyr[5] << 8))) * 0.1f;
            imu->gyroZ = (float)((int16_t)((uint16_t)last_gyr[6] | ((uint16_t)last_gyr[7] << 8))) * 0.1f;
        }
        else {
            // 필요시: 예외 처리/로그
        }
    }
}

// Single Motor Controller Functions ----------------------------------------------------
void motor_encoder_read(Motor *m, float32_t cutoff)
{
	// sensor cutoff resetting
	m->sensor_cutoff = cutoff;

	// state update
	m->pos_old = m->pos;
	m->vel_old = m->vel;
	m->acc_old = m->acc;
	m->pos_error_old = m->pos_error;
	m->pos_I_term_old = m->pos_I_term;
	m->pos_D_term_old = m->pos_D_term;
	m->vel_error_old = m->vel_error;
	m->vel_I_term_old = m->vel_I_term;

	m->control_input_old = m->control_input;

	const float32_t P_MIN = -32768, P_MAX = 32768;
	uint8_t buf[8], last[8]; int got = 0;
	while (xQueueReceive(m->canRxQueue, buf, 0) == pdPASS) { memcpy(last, buf, 8); got = 1; }
	if (got)
	{
		// CAN 메시지가 이미 수신되었을 시
		unsigned int p_int = ((last[1]<<8)|last[2]);
		float32_t pulses = (float32_t) uint_to_float32_t(p_int, P_MIN, P_MAX, 16);
		//printf("motor pulses: %f", pulses);
		m->pos = (pulses * (2 * pi /m->encoder_pulses)) ; // load단 position (rad) 값 피드백
	}
	else
	{
//		sta = 2;
//		Error_Handler();
		// 수신 실패 시에도 이전 pos 값을 그대로 유지
		m->pos = m->pos_old;
		//printf("Warning: can not read encoder position of ID %d", m->id);
	}
	// 어쨌든 vel, acc 업데이트는 수행
	m->vel = tustin_derivative(m->pos, m->pos_old, m->vel_old, m->sensor_cutoff); // rad/s 값 계산
	m->acc = tustin_derivative(m->vel, m->vel_old, m->acc_old, m->sensor_cutoff); // rad/s^2 값 계산
}

void motor_pos_pid_gain_setting(Motor *m, float32_t kp, float32_t kd, float32_t ki, float32_t cutoff)
{
	m->pos_kp = kp;
	m->pos_kd = kd;
	m->pos_ki = ki;
	m->cutoff_pos_pid = cutoff;
}

void motor_vel_pi_gain_setting(Motor *m, float32_t kp, float32_t ki)
{
	m->vel_kp = kp;
	m->vel_ki = ki;
}

void motor_pos_pid(Motor *m, float32_t pos_ref)
{
	float32_t tau = 1 / (2 * pi * m->cutoff_pos_pid);

	m->pos_ref = pos_ref;

	m->pos_error = m->pos_ref - m->pos;

	m->pos_P_term = m->pos_kp * m->pos_error;
	m->pos_I_term = m->pos_ki * Ts / 2.0 * (m->pos_error + m->pos_error_old) + m->pos_I_term_old;
	m->pos_D_term = 2.0 * m->pos_kd / (2.0 * tau + Ts) * (m->pos_error - m->pos_error_old) - (Ts - 2.0 * tau) / (2.0 * tau + Ts) * m->pos_D_term_old;

	m->control_input = (m->pos_P_term + m->pos_I_term + m->pos_D_term) /m->gear_ratio /m->Kt; // motor torque -> load torque -> current converting

	// 매 주기 anti-windup term 리셋 (추후 saturation이 발생하게 되면 값이 덧씌워짐)
	m->control_input_excess = 0.0f;
	if (m->control_input > m->upper_CL) {
		m->control_input_excess = (m->control_input - m->upper_CL) * m->Kt * m->gear_ratio;
		m->control_input = m->upper_CL; // upper bound saturation (rated current limit)
	}
	if (m->control_input < m->lower_CL) {
		m->control_input_excess = (m->control_input - m->lower_CL) * m->Kt * m->gear_ratio;
		m->control_input = m->lower_CL; // lower bound saturation (rated current limit)
	}
}

void motor_vel_pid(Motor *m, float32_t vel_ref)
{
	m->vel_ref = vel_ref;

	m->vel_error = m->vel_ref - m->vel;

	m->vel_P_term = m->vel_kp * m->vel_error;
	m->vel_I_term = m->vel_ki * Ts / 2.0 * (m->vel_error + m->vel_error_old) + m->vel_I_term_old;

	m->control_input = (m->vel_P_term + m->vel_I_term) /m->gear_ratio /m->Kt; // motor torque -> load torque -> current converting

	// 매 주기 anti-windup term 리셋 (추후 saturation이 발생하게 되면 값이 덧씌워짐)
	m->control_input_excess = 0.0f;
	if (m->control_input > m->upper_CL) {
		m->control_input_excess = (m->control_input - m->upper_CL) * m->Kt * m->gear_ratio;
		m->control_input = m->upper_CL; // upper bound saturation (rated current limit)
	}
	if (m->control_input < m->lower_CL) {
		m->control_input_excess = (m->control_input - m->lower_CL) * m->Kt * m->gear_ratio;
		m->control_input = m->lower_CL; // lower bound saturation (rated current limit)
	}
}

void motor_feedforward_torque(Motor *m, float32_t tor_ref)
{
	m->control_input = tor_ref /m->gear_ratio /m->Kt; // motor torque -> load torque -> current converting

	// 매 주기 anti-windup term 리셋 (추후 saturation이 발생하게 되면 값이 덧씌워짐)
	m->control_input_excess = 0.0f;
	if (m->control_input > m->upper_CL) {
		m->control_input_excess = (m->control_input - m->upper_CL) * m->Kt * m->gear_ratio;
		m->control_input = m->upper_CL; // upper bound saturation (rated current limit)
	}
	if (m->control_input < m->lower_CL) {
		m->control_input_excess = (m->control_input - m->lower_CL) * m->Kt * m->gear_ratio;
		m->control_input = m->lower_CL; // lower bound saturation (rated current limit)
	}
}

// 3-DoF Manipulator Task Space Controller Functions ----------------------------------------------------
void robot_forward_kinematics_cal(Manipulator *r)
{
	// 1. pre-term calculation
	const float32_t s_1 = sinf(r->q_bi.pData[0]);
	const float32_t c_1 = cosf(r->q_bi.pData[0]);
	const float32_t s_m = sinf(r->q_bi.pData[1]);
	const float32_t c_m = cosf(r->q_bi.pData[1]);
	const float32_t s_b = sinf(r->q_bi.pData[2]);
	const float32_t c_b = cosf(r->q_bi.pData[2]);
	// 2. task space state update
	for (int i = 0; i < NUM_TASK_DEG; ++i) {
		r->posXYZ_ref_old.pData[i] = r->posXYZ_ref.pData[i];
		r->posXYZ_old.pData[i] = r->posXYZ.pData[i];
		r->velXYZ_old.pData[i] = r->velXYZ.pData[i];
		r->accXYZ_old.pData[i] = r->accXYZ.pData[i];
	}
	r->posXYZ.pData[0] = c_1 * (r->l2 * c_m + r->l3 * c_b);
	r->posXYZ.pData[1] = s_1 * (r->l2 * c_m + r->l3 * c_b);
	r->posXYZ.pData[2] = r->l1 + r->l2 * s_m + r->l3 * s_b;
	if (arm_mat_mult_f32(&r->jacb_bi, &r->qdot_bi, &r->velXYZ) != ARM_MATH_SUCCESS) { sta=4; Error_Handler(); }
	for (int i = 0; i < NUM_TASK_DEG; ++i) {
		r->accXYZ.pData[i] = tustin_derivative(r->velXYZ.pData[i], r->velXYZ_old.pData[i], r->accXYZ_old.pData[i], 70.0f);
	}
}

void robot_model_param_cal(Manipulator *r)
{
	// 1. pre-term calculation
	const float32_t s_1 = sinf(r->q_bi.pData[0]);
	const float32_t c_1 = cosf(r->q_bi.pData[0]);
	const float32_t s_m = sinf(r->q_bi.pData[1]);
	const float32_t c_m = cosf(r->q_bi.pData[1]);
	const float32_t s_b = sinf(r->q_bi.pData[2]);
	const float32_t c_b = cosf(r->q_bi.pData[2]);
	const float32_t s_bm = sinf(r->q_bi.pData[2] - r->q_bi.pData[1]);
	const float32_t c_bm = cosf(r->q_bi.pData[2] - r->q_bi.pData[1]);

	// 2. model params update (Jacobian 채우기)
	r->jacb_bi.pData[0 * r->jacb_bi.numCols + 0] = -s_1 * (r->l2 * c_m + r->l3 * c_b);
	r->jacb_bi.pData[0 * r->jacb_bi.numCols + 1] = -r->l2 * c_1 * s_m;
	r->jacb_bi.pData[0 * r->jacb_bi.numCols + 2] = -r->l3 * c_1 * s_b;
	r->jacb_bi.pData[1 * r->jacb_bi.numCols + 0] = c_1 * (r->l2 * c_m + r->l3 * c_b);
	r->jacb_bi.pData[1 * r->jacb_bi.numCols + 1] = -r->l2 * s_1 * s_m;
	r->jacb_bi.pData[1 * r->jacb_bi.numCols + 2] = -r->l3 * s_1 * s_b;
	r->jacb_bi.pData[2 * r->jacb_bi.numCols + 0] = 0.0f;
	r->jacb_bi.pData[2 * r->jacb_bi.numCols + 1] = r->l2 * c_m;
	r->jacb_bi.pData[2 * r->jacb_bi.numCols + 2] = r->l3 * c_b;
	if (arm_mat_trans_f32(&r->jacb_bi, &r->jacb_bi_trans) != ARM_MATH_SUCCESS)  { sta=4; Error_Handler(); }

	// 3. model params update (Manipulator Dynamics model 채우기)
	float32_t l2_cm_d3_cb = r->l2 * c_m + r->d3 * c_b;
	r->M_bi.pData[0 * r->M_bi.numCols + 0] = r->J1
											+ r->m2 * (r->d2 * c_m) * (r->d2 * c_m)
											+ r->m3 *  l2_cm_d3_cb * l2_cm_d3_cb;
	r->M_bi.pData[0 * r->M_bi.numCols + 1] = - r->m2 * r->d2 * r->d2 * s_m * c_m
											- r->m3 * l2_cm_d3_cb * r->l2 * s_m;
	r->M_bi.pData[0 * r->M_bi.numCols + 2] = - r->m3 * l2_cm_d3_cb * r->d3 * s_b;
	r->M_bi.pData[1 * r->M_bi.numCols + 0] = r->M_bi.pData[0 * r->M_bi.numCols + 1];
	r->M_bi.pData[1 * r->M_bi.numCols + 1] = r->J2
											+ r->m3 * r->l2 * r->l2;
	r->M_bi.pData[1 * r->M_bi.numCols + 2] = r->m3 * r->l2 * r->d3 * c_bm;
	r->M_bi.pData[2 * r->M_bi.numCols + 0] = r->M_bi.pData[0 * r->M_bi.numCols + 2];
	r->M_bi.pData[2 * r->M_bi.numCols + 1] = r->M_bi.pData[1 * r->M_bi.numCols + 2];
	r->M_bi.pData[2 * r->M_bi.numCols + 2] = r->J3;
	r->C_bi.pData[0]= 2.0f * (- r->m2 * r->d2 * r->d2 * c_m * s_m * r->qdot_bi.pData[1]
								- r->m3 * (r->l2 * c_m + r->d3 * c_b) * ((r->l2 * s_m + r->d3 * s_b) * r->qdot_bi.pData[1] + r->d3 * s_b * (r->qdot_bi.pData[2] - r->qdot_bi.pData[1]))
							 ) * r->qdot_bi.pData[0];
	r->C_bi.pData[1] = - r->m3 * r->l2 * r->d3 * s_bm * (r->qdot_bi.pData[2] + r->qdot_bi.pData[1]) * (r->qdot_bi.pData[2] - r->qdot_bi.pData[1]);
	r->C_bi.pData[2] = r->m3 * r->l2 * r->d3 * s_bm * (r->qdot_bi.pData[1] * r->qdot_bi.pData[1]);
	r->G_bi.pData[0] = 0.0f;
	r->G_bi.pData[1] = g * (r->m2 * r->d2 + r->m3 * r->l2) * c_m;
	r->G_bi.pData[2] = g * r->m3 * r->d3 * c_b;

	// 5.Singular Point에 가까운지 여부에 따라 Jacobian Inverse와 Taskspace Mass Matrix 분리해서 계산
	// L = l2*cos(qm) + l3*cos(qb)
	float32_t L = r->l2 * c_m + r->l3 * c_b;
	// Δ = cos(qb) * sin(qm) - cos(qm) * sin(qb) = sin(qm - qb)
	float32_t Delta = c_b * s_m - c_m * s_b;
	// L, Delta 계산 직후 크기가 너무 작지 않은지 확인 (Singular Point에 가까운지 확인)
	float32_t epsL = fmaxf(1e-6f*(r->l2 + r->l3), FLT_EPSILON*(r->l2 + r->l3));
	float32_t epsD = fmaxf(1e-6f,               FLT_EPSILON);
	if (fabsf(L) < epsL || fabsf(Delta) < epsD) // Singular Point에 가까우면 0으로 나누게 되는 Fault 상황이 발생하기 때문에 해당 경우에는 DLS 사용
	{
	    // ----- DLS fallback: J^T (J J^T + λ^2 I)^{-1} -----
		// Jacobian의 Inverse 계산
	    float32_t JJt_buf[9], JJt_d_buf[9], invJJt_buf[9];
	    arm_matrix_instance_f32 JJt, JJt_d, invJJt;
	    arm_mat_init_f32(&JJt,   3,3, JJt_buf);
	    arm_mat_init_f32(&JJt_d, 3,3, JJt_d_buf);
	    arm_mat_init_f32(&invJJt,3,3, invJJt_buf);
	    if (arm_mat_mult_f32(&r->jacb_bi, &r->jacb_bi_trans, &JJt) != ARM_MATH_SUCCESS) { sta=4; Error_Handler(); }
	    float32_t tr = JJt_buf[0] + JJt_buf[4] + JJt_buf[8];
	    float32_t lambda = 0.05f * (tr/3.0f + 1e-6f);
	    float32_t lambda2 = lambda*lambda;
	    for (int i=0;i<9;i++) JJt_d_buf[i] = JJt_buf[i];
	    JJt_d_buf[0]+=lambda2; JJt_d_buf[4]+=lambda2; JJt_d_buf[8]+=lambda2;
	    if (arm_mat_inverse_f32(&JJt_d, &invJJt) != ARM_MATH_SUCCESS) { sta=4; Error_Handler(); }
	    if (arm_mat_mult_f32(&r->jacb_bi_trans, &invJJt, &r->jacb_bi_inv) != ARM_MATH_SUCCESS) { sta=4; Error_Handler(); }
	    // Jacobian의 Inverse의 Transpose 계산
		if (arm_mat_trans_f32(&r->jacb_bi_inv, &r->jacb_bi_trans_inv) != ARM_MATH_SUCCESS) { sta=4; Error_Handler(); }
		// Taskspace Mass Matrix 계산
		float32_t Minv_buf[9], A_buf[9], Ad_buf[9], Lambda_buf[9], tmp_buf[9];
		arm_matrix_instance_f32 Minv, A, Ad, Lambda, tmp;
		arm_mat_init_f32(&Minv,  3,3, Minv_buf);
		arm_mat_init_f32(&A,     3,3, A_buf);
		arm_mat_init_f32(&Ad,    3,3, Ad_buf);
		arm_mat_init_f32(&Lambda,3,3, Lambda_buf);
		arm_mat_init_f32(&tmp,   3,3, tmp_buf);
		if (arm_mat_inverse_f32(&r->M_bi, &Minv) == ARM_MATH_SUCCESS) { // M이 특이행렬이 아니면 계산하고, 특이행렬이면 안전하게 이전값 유지
		    // A = J * Minv * J^T
		    if (arm_mat_mult_f32(&r->jacb_bi, &Minv, &tmp) != ARM_MATH_SUCCESS) { sta=4; Error_Handler(); }
		    if (arm_mat_mult_f32(&tmp, &r->jacb_bi_trans, &A) != ARM_MATH_SUCCESS) { sta=4; Error_Handler(); }
		    // 댐핑(선택): A_d = A + μ^2 I
		    for (int i=0;i<9;i++) Ad_buf[i] = A_buf[i];
		    float32_t mu2 = 0.0f; // 필요 시 1e-4 ~ 1e-2 범위
		    Ad_buf[0]+=mu2; Ad_buf[4]+=mu2; Ad_buf[8]+=mu2;
		    if (arm_mat_inverse_f32(&Ad, &Lambda) != ARM_MATH_SUCCESS) { sta=4; Error_Handler(); }
		    // 최종 작업공간 관성 M_bi_task = Lambda
		    for (int i=0;i<9;i++) r->M_bi_task.pData[i] = Lambda_buf[i];
		}
		// DOB를 위한 Nominal Taskspace Mass Matrix 계산
		r->M_bi_task_nominal.pData[0 * r->M_bi_task_nominal.numCols + 0] = r->M_bi_task.pData[0 * r->M_bi_task.numCols + 0];
		r->M_bi_task_nominal.pData[0 * r->M_bi_task_nominal.numCols + 1] = 0;
		r->M_bi_task_nominal.pData[0 * r->M_bi_task_nominal.numCols + 2] = 0;
		r->M_bi_task_nominal.pData[1 * r->M_bi_task_nominal.numCols + 0] = 0;
		r->M_bi_task_nominal.pData[1 * r->M_bi_task_nominal.numCols + 1] = r->M_bi_task.pData[1 * r->M_bi_task.numCols + 1];
		r->M_bi_task_nominal.pData[1 * r->M_bi_task_nominal.numCols + 2] = 0;
		r->M_bi_task_nominal.pData[2 * r->M_bi_task_nominal.numCols + 0] = 0;
		r->M_bi_task_nominal.pData[2 * r->M_bi_task_nominal.numCols + 1] = 0;
		r->M_bi_task_nominal.pData[2 * r->M_bi_task_nominal.numCols + 2] = r->M_bi_task.pData[2 * r->M_bi_task.numCols + 2];
	}
	else // Singular Point에 가깝지 않으면 직접 Jacobian의 Inverse 계산
	{
		// Jacobian의 Inverse 계산
	    r->jacb_bi_inv.pData[0*r->jacb_bi_inv.numCols + 0] = -s_1 / L;
	    r->jacb_bi_inv.pData[0*r->jacb_bi_inv.numCols + 1] =  c_1 / L;
	    r->jacb_bi_inv.pData[0*r->jacb_bi_inv.numCols + 2] =  0.0f;
	    r->jacb_bi_inv.pData[1*r->jacb_bi_inv.numCols + 0] = -c_1 * c_b / (r->l2 * Delta);
	    r->jacb_bi_inv.pData[1*r->jacb_bi_inv.numCols + 1] = -c_b * s_1 / (r->l2 * Delta);
	    r->jacb_bi_inv.pData[1*r->jacb_bi_inv.numCols + 2] = -s_b / (r->l2 * Delta);
	    r->jacb_bi_inv.pData[2*r->jacb_bi_inv.numCols + 0] =  c_1 * c_m / (r->l3 * Delta);
	    r->jacb_bi_inv.pData[2*r->jacb_bi_inv.numCols + 1] =  c_m * s_1 / (r->l3 * Delta);
	    r->jacb_bi_inv.pData[2*r->jacb_bi_inv.numCols + 2] =  s_m / (r->l3 * Delta);
	    // Jacobian의 Inverse의 Transpose 계산
	    if (arm_mat_trans_f32(&r->jacb_bi_inv, &r->jacb_bi_trans_inv) != ARM_MATH_SUCCESS) { sta=4; Error_Handler(); }
	    // Taskspace Mass Matrix 계산
		float32_t MJI_buf[9] = {0, 0, 0, 0, 0, 0, 0, 0, 0};
		arm_matrix_instance_f32 MJI;
		arm_mat_init_f32(&MJI,  3, 3, MJI_buf);
		if (arm_mat_mult_f32(&r->M_bi, &r->jacb_bi_inv, &MJI) != ARM_MATH_SUCCESS) { sta=4; Error_Handler(); }
		if (arm_mat_mult_f32(&r->jacb_bi_trans_inv, &MJI, &r->M_bi_task) != ARM_MATH_SUCCESS) { sta=4; Error_Handler(); }
		// DOB를 위한 Nominal Taskspace Mass Matrix 계산
		r->M_bi_task_nominal.pData[0 * r->M_bi_task_nominal.numCols + 0] = r->M_bi_task.pData[0 * r->M_bi_task.numCols + 0];
		r->M_bi_task_nominal.pData[0 * r->M_bi_task_nominal.numCols + 1] = 0;
		r->M_bi_task_nominal.pData[0 * r->M_bi_task_nominal.numCols + 2] = 0;
		r->M_bi_task_nominal.pData[1 * r->M_bi_task_nominal.numCols + 0] = 0;
		r->M_bi_task_nominal.pData[1 * r->M_bi_task_nominal.numCols + 1] = r->M_bi_task.pData[1 * r->M_bi_task.numCols + 1];
		r->M_bi_task_nominal.pData[1 * r->M_bi_task_nominal.numCols + 2] = 0;
		r->M_bi_task_nominal.pData[2 * r->M_bi_task_nominal.numCols + 0] = 0;
		r->M_bi_task_nominal.pData[2 * r->M_bi_task_nominal.numCols + 1] = 0;
		r->M_bi_task_nominal.pData[2 * r->M_bi_task_nominal.numCols + 2] = r->M_bi_task.pData[2 * r->M_bi_task.numCols + 2];
	}
}

void robot_state_update(Manipulator *r)
{
	// 1. joint state update
	for (int i = 0; i < NUM_MOTORS; ++i) {
		r->q_bi.pData		 [i] = r->axis_configuration[i] * r->motors[i].pos + homing_q_bi.pData[i];
		r->q_bi_old.pData	 [i] = r->axis_configuration[i] * r->motors[i].pos_old + homing_q_bi.pData[i];
		r->qdot_bi.pData	 [i] = r->axis_configuration[i] * r->motors[i].vel;
		r->qdot_bi_old.pData [i] = r->axis_configuration[i] * r->motors[i].vel_old;
		r->qddot_bi.pData	 [i] = r->axis_configuration[i] * r->motors[i].acc;
		r->qddot_bi_old.pData[i] = r->axis_configuration[i] * r->motors[i].acc_old;
		r->tau_bi_excess.pData[i] = r->axis_configuration[i] * r->motors[i].control_input_excess;
	}

	// 2. Range of Motion Checking
	r->q.pData[0] = r->q_bi.pData[0];
	r->q.pData[1] = r->q_bi.pData[1];
	r->q.pData[2] = r->q_bi.pData[2] - r->q_bi.pData[1];
	for (int i = 0; i < NUM_MOTORS; ++i) {
		if (r->q.pData[i] > r->q_upper_ROM[i]) { sta=5; Error_Handler(); }
		else if (r->q.pData[i] < r->q_lower_ROM[i]) { sta=5; Error_Handler(); }
	}

	// 2. model params update
	robot_model_param_cal(r);

	// 3. task space state update
	robot_forward_kinematics_cal(r);

	// 4. manipulator task space pid control state update
	for (int i = 0; i < NUM_TASK_DEG; ++i) {
		r->pos_error_old.pData[i] = r->pos_error.pData[i];
		r->pos_I_term_old.pData[i] = r->pos_I_term.pData[i];
		r->pos_D_term_old.pData[i] = r->pos_D_term.pData[i];
	}

	// 5. manipulator task space DOB control state update
	for (int i = 0; i < NUM_MOTORS; ++i) {
		r->DOB_lhs_old.pData[i] = r->DOB_lhs.pData[i];
		r->DOB_filtered_lhs_old.pData[i] = r->DOB_filtered_lhs.pData[i];
		r->DOB_rhs_old.pData[i] = r->DOB_rhs.pData[i];
		r->DOB_filtered_rhs_old.pData[i] = r->DOB_filtered_rhs.pData[i];
	}

	// 6. manipulator control input update
	for (int i = 0; i < NUM_MOTORS; ++i) {
		r->tau_bi_old.pData[i] = r->tau_bi.pData[i];
		r->pos_pid_output_excess_old.pData[i] = r->pos_pid_output_excess.pData[i];
	}

	// 7. anti-windup term update
	if (arm_mat_mult_f32(&r->jacb_bi_trans_inv, &r->tau_bi_excess, &r->pos_pid_output_excess) != ARM_MATH_SUCCESS) { sta=4; Error_Handler(); }
}

void robot_pos_pid_gain_setting(Manipulator *r, float32_t* kp, float32_t* kd, float32_t* ki, float32_t* k_windup, float32_t* cutoff)
{
	for (int i = 0; i < NUM_TASK_DEG; ++i) {
		r->pos_kp[i] = kp[i];
		r->pos_kd[i] = kd[i];
		r->pos_ki[i] = ki[i];
		r->pos_k_windup[i] = k_windup[i];
		r->cutoff_pos_pid[i] = cutoff[i];
	}
}

void robot_pos_pid(Manipulator *r, arm_matrix_instance_f32 pos_ref)
{
	for (int i = 0; i < NUM_TASK_DEG; ++i) {
		float32_t tau = 1 / (2 * pi * r->cutoff_pos_pid[i]);

		r->posXYZ_ref.pData[i] = pos_ref.pData[i];

		r->pos_error.pData[i] = r->posXYZ_ref.pData[i] - r->posXYZ.pData[i];

		r->pos_P_term.pData[i] = r->pos_kp[i] * r->pos_error.pData[i];
		r->pos_I_term.pData[i] = r->pos_ki[i] * Ts / 2.0 * (r->pos_error.pData[i] - r->pos_k_windup[i] * r->pos_pid_output_excess.pData[i] + r->pos_error_old.pData[i] - r->pos_k_windup[i] * r->pos_pid_output_excess_old.pData[i]) + r->pos_I_term_old.pData[i];
		r->pos_D_term.pData[i] = 2.0 * r->pos_kd[i] / (2.0 * tau + Ts) * (r->pos_error.pData[i] - r->pos_error_old.pData[i]) - (Ts - 2.0 * tau) / (2.0 * tau + Ts) * r->pos_D_term_old.pData[i];

		r->pos_pid_output.pData[i] = (r->pos_P_term.pData[i] + r->pos_I_term.pData[i] + r->pos_D_term.pData[i]);
	}

	if (arm_mat_mult_f32(&r->jacb_bi_trans, &r->pos_pid_output, &r->tau_bi) != ARM_MATH_SUCCESS) { sta=4; Error_Handler(); }
}
// Trajectory Making Functions ----------------------------------------------------
void set_trajectory(Manipulator *r, Trajectory *traj, float32_t task_time, float32_t *final_pos)
{
	bool same_pos = (final_pos[0]==traj->final_pos[0] &&
					 final_pos[1]==traj->final_pos[1] &&
					 final_pos[2]==traj->final_pos[2]);
	bool same_T   = fabsf(task_time - traj->task_time) < 1e-6f;

	float32_t now = (float32_t)ctrl_time_ms/1000.f;
	bool still_running = (now - traj->initial_time) < traj->task_time;

	if (still_running) return; // 아직 이전 task 수행중이면 무조건 스킵
	else // 이전 task가 완료된 상황일 때,
	{
		if ((same_pos && same_T) || still_running) return; // 같은 목표/시간이 들어온 경우이면 스킵
		else // 다른 목표 혹은 다른 시간이 들어온 경우이면 trajectory 새로 생성
		{
			traj->task_time = task_time;
			traj->initial_time = (float32_t) ctrl_time_ms / 1000.0f;
			traj->final_time = traj->initial_time + traj->task_time;

			for (int i=0; i<NUM_TASK_DEG; ++i)
			{
				traj->initial_pos[i] = r->posXYZ.pData[i];
				traj->initial_vel[i] = 0.0f;
				traj->initial_acc[i] = 0.0f;

				traj->final_pos[i] = final_pos[i];
				traj->final_vel[i] = 0.0f;
				traj->final_acc[i] = 0.0f;
			}

			float32_t deltaX = traj->final_pos[0] - traj->initial_pos[0];
			traj->xpos_coefficient[0] = traj->initial_pos[0];
			traj->xpos_coefficient[1] = traj->initial_vel[0];
			traj->xpos_coefficient[2] = 0.5f * traj->initial_acc[0];
			traj->xpos_coefficient[3] = ( 20 * deltaX - 12 * traj->initial_vel[0] * traj->task_time -   3 * traj->initial_acc[0] * traj->task_time * traj->task_time) / (2 * traj->task_time * traj->task_time * traj->task_time);
			traj->xpos_coefficient[4] = (-15 * deltaX +  8 * traj->initial_vel[0] * traj->task_time + 1.5 * traj->initial_acc[0] * traj->task_time * traj->task_time) / (1 * traj->task_time * traj->task_time * traj->task_time * traj->task_time);
			traj->xpos_coefficient[5] = ( 12 * deltaX -  6 * traj->initial_vel[0] * traj->task_time -   1 * traj->initial_acc[0] * traj->task_time * traj->task_time) / (2 * traj->task_time * traj->task_time * traj->task_time * traj->task_time * traj->task_time);

			float32_t deltaY = traj->final_pos[1] - traj->initial_pos[1];
			traj->ypos_coefficient[0] = traj->initial_pos[1];
			traj->ypos_coefficient[1] = traj->initial_vel[1];
			traj->ypos_coefficient[2] = 0.5f * traj->initial_acc[1];
			traj->ypos_coefficient[3] = ( 20 * deltaY - 12 * traj->initial_vel[1] * traj->task_time -   3 * traj->initial_acc[1] * traj->task_time * traj->task_time) / (2 * traj->task_time * traj->task_time * traj->task_time);
			traj->ypos_coefficient[4] = (-15 * deltaY +  8 * traj->initial_vel[1] * traj->task_time + 1.5 * traj->initial_acc[1] * traj->task_time * traj->task_time) / (1 * traj->task_time * traj->task_time * traj->task_time * traj->task_time);
			traj->ypos_coefficient[5] = ( 12 * deltaY -  6 * traj->initial_vel[1] * traj->task_time -   1 * traj->initial_acc[1] * traj->task_time * traj->task_time) / (2 * traj->task_time * traj->task_time * traj->task_time * traj->task_time * traj->task_time);

			float32_t deltaZ = traj->final_pos[2] - traj->initial_pos[2];
			traj->zpos_coefficient[0] = traj->initial_pos[2];
			traj->zpos_coefficient[1] = traj->initial_vel[2];
			traj->zpos_coefficient[2] = 0.5f * traj->initial_acc[2];
			traj->zpos_coefficient[3] = ( 20 * deltaZ - 12 * traj->initial_vel[2] * traj->task_time -   3 * traj->initial_acc[2] * traj->task_time * traj->task_time) / (2 * traj->task_time * traj->task_time * traj->task_time);
			traj->zpos_coefficient[4] = (-15 * deltaZ +  8 * traj->initial_vel[2] * traj->task_time + 1.5 * traj->initial_acc[2] * traj->task_time * traj->task_time) / (1 * traj->task_time * traj->task_time * traj->task_time * traj->task_time);
			traj->zpos_coefficient[5] = ( 12 * deltaZ -  6 * traj->initial_vel[2] * traj->task_time -   1 * traj->initial_acc[2] * traj->task_time * traj->task_time) / (2 * traj->task_time * traj->task_time * traj->task_time * traj->task_time * traj->task_time);
		}
	}
}

void get_target_point(Trajectory *traj, arm_matrix_instance_f32 pos_ref)
{
	float32_t t = ((float32_t) ctrl_time_ms / 1000.0f) - traj->initial_time;
	if (t < traj->task_time)
	{
		pos_ref.pData[0] = traj->xpos_coefficient[0] + traj->xpos_coefficient[1] *t + traj->xpos_coefficient[2] *t*t + traj->xpos_coefficient[3] *t*t*t + traj->xpos_coefficient[4] *t*t*t*t + traj->xpos_coefficient[5] *t*t*t*t*t;
		pos_ref.pData[1] = traj->ypos_coefficient[0] + traj->ypos_coefficient[1] *t + traj->ypos_coefficient[2] *t*t + traj->ypos_coefficient[3] *t*t*t + traj->ypos_coefficient[4] *t*t*t*t + traj->ypos_coefficient[5] *t*t*t*t*t;
		pos_ref.pData[2] = traj->zpos_coefficient[0] + traj->zpos_coefficient[1] *t + traj->zpos_coefficient[2] *t*t + traj->zpos_coefficient[3] *t*t*t + traj->zpos_coefficient[4] *t*t*t*t + traj->zpos_coefficient[5] *t*t*t*t*t;
	}
	else
	{
		for(int i=0; i<NUM_TASK_DEG; ++i)
		{
			pos_ref.pData[i] = traj->final_pos[i];
		}
	}
}

/* USER CODE END 0 */

int main(void)
{

  /* USER CODE BEGIN 1 */
	// 모터 객체 불변 파라미터 초기화
	for (int i = 0; i < NUM_MOTORS; ++i) {
		strawberry_robot.motors[i].id = i + 1;  // ID 1, 2, 3, ...
		strawberry_robot.motors[i].current_motor_mode = 0;
		strawberry_robot.motors[i].encoder_pulses = 16384;
		strawberry_robot.motors[i].gear_ratio = 10;
		strawberry_robot.motors[i].Kt = 0.123;
		strawberry_robot.motors[i].canRxQueue = xQueueCreate(8, sizeof(uint8_t[8]));  // 8바이트 버퍼
		if (strawberry_robot.motors[i].canRxQueue == NULL) {
			sta = 3;
			Error_Handler();
		}
		strawberry_robot.motors[i].upper_CL = 7.2;
		strawberry_robot.motors[i].lower_CL = -7.2;
	}
	// 가속도, 각속도계 파라미터 초기화
	for (int i = 0; i < NUM_IMUS; ++i) {
		strawberry_robot.IMUs[i].id = i + 4;    // ID 4, 5, 6, ...
		strawberry_robot.IMUs[i].canRxQueue_accel = xQueueCreate(8, sizeof(uint8_t[8]));  // 8바이트 버퍼
		strawberry_robot.IMUs[i].canRxQueue_gyro = xQueueCreate(8, sizeof(uint8_t[8]));  // 8바이트 버퍼
	}
	// 로봇 객체 불변 파라미터 초기화
	arm_mat_init_f32(&homing_q_bi, NUM_MOTORS, 1, homing_q_bi_buffer);
	arm_mat_init_f32(&homing_posXYZ, NUM_TASK_DEG, 1, homing_posXYZ_buffer);
	arm_mat_init_f32(&target_posXYZ, NUM_TASK_DEG, 1, target_posXYZ_buffer);

	strawberry_robot.current_robot_mode = 0;
	strawberry_robot.desired_robot_mode = 0;

	strawberry_robot.axis_configuration[0] = -1;
	strawberry_robot.axis_configuration[1] = -1;
	strawberry_robot.axis_configuration[2] = 1;

	strawberry_robot.q_lower_ROM[0] = -pi / 2;
	strawberry_robot.q_upper_ROM[0] = pi / 2;
	strawberry_robot.q_lower_ROM[1] = 0;
	strawberry_robot.q_upper_ROM[1] = 120 * (pi/180);
	strawberry_robot.q_lower_ROM[2] = -160 * (pi/180);
	strawberry_robot.q_upper_ROM[2] = -40 * (pi/180);

	// link length setting
	strawberry_robot.l1 = 0.176;
	strawberry_robot.l2 = 0.46;
	strawberry_robot.l3 = 0.46;

	// link mass setting
	strawberry_robot.m1 = 3.82406;
	strawberry_robot.m2 = 0.17634;
	strawberry_robot.m3 = 1.46067;

	// link CoM position setting
	strawberry_robot.d2 = 0.23;
	strawberry_robot.d3 = 0.18432;

	// link inertia setting
	strawberry_robot.J1 = 0.02450771104;
	strawberry_robot.J2 = 0.00811740221;
	strawberry_robot.J3 = 0.11079467270;

	// 로봇 joint state matrix 연결
	arm_mat_init_f32(&strawberry_robot.q, NUM_MOTORS, 1, strawberry_robot.q_buffer);
	arm_mat_init_f32(&strawberry_robot.q_bi, NUM_MOTORS, 1, strawberry_robot.q_bi_buffer);
	arm_mat_init_f32(&strawberry_robot.q_bi_old, NUM_MOTORS, 1, strawberry_robot.q_bi_old_buffer);
	arm_mat_init_f32(&strawberry_robot.qdot_bi, NUM_MOTORS, 1, strawberry_robot.qdot_bi_buffer);
	arm_mat_init_f32(&strawberry_robot.qdot_bi_old, NUM_MOTORS, 1, strawberry_robot.qdot_bi_old_buffer);
	arm_mat_init_f32(&strawberry_robot.qddot_bi, NUM_MOTORS, 1, strawberry_robot.qddot_bi_buffer);
	arm_mat_init_f32(&strawberry_robot.qddot_bi_old, NUM_MOTORS, 1, strawberry_robot.qddot_bi_old_buffer);
	// 로봇 task space state matrix 연결
	arm_mat_init_f32(&strawberry_robot.posXYZ_ref, NUM_TASK_DEG, 1, strawberry_robot.posXYZ_ref_buffer);
	arm_mat_init_f32(&strawberry_robot.posXYZ_ref_old, NUM_TASK_DEG, 1, strawberry_robot.posXYZ_ref_old_buffer);
	arm_mat_init_f32(&strawberry_robot.posXYZ, NUM_TASK_DEG, 1, strawberry_robot.posXYZ_buffer);
	arm_mat_init_f32(&strawberry_robot.posXYZ_old, NUM_TASK_DEG, 1, strawberry_robot.posXYZ_old_buffer);
	arm_mat_init_f32(&strawberry_robot.velXYZ, NUM_TASK_DEG, 1, strawberry_robot.velXYZ_buffer);
	arm_mat_init_f32(&strawberry_robot.velXYZ_old, NUM_TASK_DEG, 1, strawberry_robot.velXYZ_old_buffer);
	arm_mat_init_f32(&strawberry_robot.accXYZ, NUM_TASK_DEG, 1, strawberry_robot.accXYZ_buffer);
	arm_mat_init_f32(&strawberry_robot.accXYZ_old, NUM_TASK_DEG, 1, strawberry_robot.accXYZ_old_buffer);
	// 로봇 model params matrix 연결
	arm_mat_init_f32(&strawberry_robot.jacb_bi, NUM_TASK_DEG, NUM_MOTORS, strawberry_robot.jacb_bi_buffer);
	arm_mat_init_f32(&strawberry_robot.jacb_bi_inv, NUM_MOTORS, NUM_TASK_DEG, strawberry_robot.jacb_bi_inv_buffer);
	arm_mat_init_f32(&strawberry_robot.jacb_bi_trans, NUM_TASK_DEG, NUM_MOTORS, strawberry_robot.jacb_bi_trans_buffer);
	arm_mat_init_f32(&strawberry_robot.jacb_bi_trans_inv, NUM_MOTORS, NUM_TASK_DEG, strawberry_robot.jacb_bi_trans_inv_buffer);
	arm_mat_init_f32(&strawberry_robot.M_bi, NUM_MOTORS, NUM_MOTORS, strawberry_robot.M_bi_buffer);
	arm_mat_init_f32(&strawberry_robot.C_bi, NUM_MOTORS, 1, strawberry_robot.C_bi_buffer);
	arm_mat_init_f32(&strawberry_robot.G_bi, NUM_MOTORS, 1, strawberry_robot.G_bi_buffer);
	arm_mat_init_f32(&strawberry_robot.M_bi_task, NUM_TASK_DEG, NUM_TASK_DEG, strawberry_robot.M_bi_task_buffer);
	arm_mat_init_f32(&strawberry_robot.M_bi_task_nominal, NUM_TASK_DEG, NUM_TASK_DEG, strawberry_robot.M_bi_task_nominal_buffer);
	// 로봇 task space pid control state matrix 연결
	arm_mat_init_f32(&strawberry_robot.pos_error, NUM_TASK_DEG, 1, strawberry_robot.pos_error_buffer);
	arm_mat_init_f32(&strawberry_robot.pos_error_old, NUM_TASK_DEG, 1, strawberry_robot.pos_error_old_buffer);
	arm_mat_init_f32(&strawberry_robot.pos_P_term, NUM_TASK_DEG, 1, strawberry_robot.pos_P_term_buffer);
	arm_mat_init_f32(&strawberry_robot.pos_I_term, NUM_TASK_DEG, 1, strawberry_robot.pos_I_term_buffer);
	arm_mat_init_f32(&strawberry_robot.pos_I_term_old, NUM_TASK_DEG, 1, strawberry_robot.pos_I_term_old_buffer);
	arm_mat_init_f32(&strawberry_robot.pos_D_term, NUM_TASK_DEG, 1, strawberry_robot.pos_D_term_buffer);
	arm_mat_init_f32(&strawberry_robot.pos_D_term_old, NUM_TASK_DEG, 1, strawberry_robot.pos_D_term_old_buffer);
	arm_mat_init_f32(&strawberry_robot.pos_pid_output, NUM_TASK_DEG, 1, strawberry_robot.pos_pid_output_buffer);

	// manipulator task space DOB control state definition
	arm_mat_init_f32(&strawberry_robot.DOB_lhs, NUM_MOTORS, 1, strawberry_robot.DOB_lhs_buffer);
	arm_mat_init_f32(&strawberry_robot.DOB_lhs_old, NUM_MOTORS, 1, strawberry_robot.DOB_lhs_old_buffer);
	arm_mat_init_f32(&strawberry_robot.DOB_filtered_lhs, NUM_MOTORS, 1, strawberry_robot.DOB_filtered_lhs_buffer);
	arm_mat_init_f32(&strawberry_robot.DOB_filtered_lhs_old, NUM_MOTORS, 1, strawberry_robot.DOB_filtered_lhs_old_buffer);
	arm_mat_init_f32(&strawberry_robot.DOB_rhs, NUM_MOTORS, 1, strawberry_robot.DOB_rhs_buffer);
	arm_mat_init_f32(&strawberry_robot.DOB_rhs_old, NUM_MOTORS, 1, strawberry_robot.DOB_rhs_old_buffer);
	arm_mat_init_f32(&strawberry_robot.DOB_filtered_rhs, NUM_MOTORS, 1, strawberry_robot.DOB_filtered_rhs_buffer);
	arm_mat_init_f32(&strawberry_robot.DOB_filtered_rhs_old, NUM_MOTORS, 1, strawberry_robot.DOB_filtered_rhs_old_buffer);

	// manipulator control input
	arm_mat_init_f32(&strawberry_robot.tau_bi, NUM_MOTORS, 1, strawberry_robot.tau_bi_buffer);
	arm_mat_init_f32(&strawberry_robot.tau_bi_old, NUM_MOTORS, 1, strawberry_robot.tau_bi_old_buffer);
	arm_mat_init_f32(&strawberry_robot.tau_bi_excess, NUM_MOTORS, 1, strawberry_robot.tau_bi_excess_buffer);
	arm_mat_init_f32(&strawberry_robot.pos_pid_output_excess, NUM_TASK_DEG, 1, strawberry_robot.pos_pid_output_excess_buffer);
	arm_mat_init_f32(&strawberry_robot.pos_pid_output_excess_old, NUM_TASK_DEG, 1, strawberry_robot.pos_pid_output_excess_old_buffer);
  /* USER CODE END 1 */

  /* MPU Configuration--------------------------------------------------------*/
  MPU_Config();

  /* MCU Configuration--------------------------------------------------------*/

  /* Reset of all peripherals, Initializes the Flash interface and the Systick. */
  HAL_Init();

  /* Configure the system clock */
  SystemClock_Config();

  /* Initialize all configured peripherals */
  MX_GPIO_Init();
  MX_DMA_Init();
  MX_FDCAN1_Init();
  MX_USART3_UART_Init();
  /* USER CODE BEGIN 2 */
  // UART3 1바이트 인터럽트 수신 시작
  uart3_rx_start_normal();
  /* USER CODE END 2 */

  /* Init scheduler */
  osKernelInitialize();

  /* Create the thread(s) */
  /* creation of Control */
  ControlHandle = osThreadNew(ControlTask, NULL, &Control_attributes);

  /* creation of DataLogging */
  DataLoggingHandle = osThreadNew(DataLoggingTask, NULL, &DataLogging_attributes);

  /* Initialize leds */
  BSP_LED_Init(LED_GREEN);
  BSP_LED_Init(LED_BLUE);
  BSP_LED_Init(LED_RED);

  /* Initialize USER push-button, will be used to trigger an interrupt each time it's pressed.*/
  BSP_PB_Init(BUTTON_USER, BUTTON_MODE_EXTI);

  /* Start scheduler */
  osKernelStart();

  /* We should never get here as control is now taken by the scheduler */

  /* Infinite loop */
  while (1)
  {

  }
}

void SystemClock_Config(void)
{
  RCC_OscInitTypeDef RCC_OscInitStruct = {0};
  RCC_ClkInitTypeDef RCC_ClkInitStruct = {0};

  /** Supply configuration update enable
  */
  HAL_PWREx_ConfigSupply(PWR_LDO_SUPPLY);

  /** Configure the main internal regulator output voltage
  */
  __HAL_PWR_VOLTAGESCALING_CONFIG(PWR_REGULATOR_VOLTAGE_SCALE1);

  while(!__HAL_PWR_GET_FLAG(PWR_FLAG_VOSRDY)) {}

  /** Initializes the RCC Oscillators according to the specified parameters
  * in the RCC_OscInitTypeDef structure.
  */
  RCC_OscInitStruct.OscillatorType = RCC_OSCILLATORTYPE_HSE;
  RCC_OscInitStruct.HSEState = RCC_HSE_ON;
  RCC_OscInitStruct.PLL.PLLState = RCC_PLL_ON;
  RCC_OscInitStruct.PLL.PLLSource = RCC_PLLSOURCE_HSE;
  RCC_OscInitStruct.PLL.PLLM = 1;
  RCC_OscInitStruct.PLL.PLLN = 100;
  RCC_OscInitStruct.PLL.PLLP = 2;
  RCC_OscInitStruct.PLL.PLLQ = 16;
  RCC_OscInitStruct.PLL.PLLR = 2;
  RCC_OscInitStruct.PLL.PLLRGE = RCC_PLL1VCIRANGE_3;
  RCC_OscInitStruct.PLL.PLLVCOSEL = RCC_PLL1VCOWIDE;
  RCC_OscInitStruct.PLL.PLLFRACN = 0;
  if (HAL_RCC_OscConfig(&RCC_OscInitStruct) != HAL_OK)
  {
    Error_Handler();
  }

  /** Initializes the CPU, AHB and APB buses clocks
  */
  RCC_ClkInitStruct.ClockType = RCC_CLOCKTYPE_HCLK|RCC_CLOCKTYPE_SYSCLK
                              |RCC_CLOCKTYPE_PCLK1|RCC_CLOCKTYPE_PCLK2
                              |RCC_CLOCKTYPE_D3PCLK1|RCC_CLOCKTYPE_D1PCLK1;
  RCC_ClkInitStruct.SYSCLKSource = RCC_SYSCLKSOURCE_PLLCLK;
  RCC_ClkInitStruct.SYSCLKDivider = RCC_SYSCLK_DIV1;
  RCC_ClkInitStruct.AHBCLKDivider = RCC_HCLK_DIV2;
  RCC_ClkInitStruct.APB3CLKDivider = RCC_APB3_DIV2;
  RCC_ClkInitStruct.APB1CLKDivider = RCC_APB1_DIV2;
  RCC_ClkInitStruct.APB2CLKDivider = RCC_APB2_DIV2;
  RCC_ClkInitStruct.APB4CLKDivider = RCC_APB4_DIV2;

  if (HAL_RCC_ClockConfig(&RCC_ClkInitStruct, FLASH_LATENCY_2) != HAL_OK)
  {
    Error_Handler();
  }
}

static void MX_FDCAN1_Init(void)
{

  hfdcan1.Instance = FDCAN1;
  hfdcan1.Init.FrameFormat = FDCAN_FRAME_CLASSIC;
  hfdcan1.Init.Mode = FDCAN_MODE_NORMAL;
  hfdcan1.Init.AutoRetransmission = ENABLE;
  hfdcan1.Init.TransmitPause = DISABLE;
  hfdcan1.Init.ProtocolException = DISABLE;
  hfdcan1.Init.NominalPrescaler = 1;
  hfdcan1.Init.NominalSyncJumpWidth = 8;
  hfdcan1.Init.NominalTimeSeg1 = 31;
  hfdcan1.Init.NominalTimeSeg2 = 8;
  hfdcan1.Init.DataPrescaler = 1;
  hfdcan1.Init.DataSyncJumpWidth = 4;
  hfdcan1.Init.DataTimeSeg1 = 5;
  hfdcan1.Init.DataTimeSeg2 = 4;
  hfdcan1.Init.MessageRAMOffset = 0;
  hfdcan1.Init.StdFiltersNbr = 0;
  hfdcan1.Init.ExtFiltersNbr = 0;
  hfdcan1.Init.RxFifo0ElmtsNbr = 64;
  hfdcan1.Init.RxFifo0ElmtSize = FDCAN_DATA_BYTES_8;
  hfdcan1.Init.RxFifo1ElmtsNbr = 0;
  hfdcan1.Init.RxFifo1ElmtSize = FDCAN_DATA_BYTES_8;
  hfdcan1.Init.RxBuffersNbr = 4;
  hfdcan1.Init.RxBufferSize = FDCAN_DATA_BYTES_8;
  hfdcan1.Init.TxEventsNbr = 16;
  hfdcan1.Init.TxBuffersNbr = 16;
  hfdcan1.Init.TxFifoQueueElmtsNbr = 32;
  hfdcan1.Init.TxFifoQueueMode = FDCAN_TX_FIFO_OPERATION;
  hfdcan1.Init.TxElmtSize = FDCAN_DATA_BYTES_8;
  if (HAL_FDCAN_Init(&hfdcan1) != HAL_OK)
  {
    Error_Handler();
  }
  /* USER CODE BEGIN FDCAN1_Init 2 */
  if(HAL_FDCAN_ActivateNotification(&hfdcan1, FDCAN_IT_RX_FIFO0_NEW_MESSAGE, 0)!= HAL_OK)
  	{
	    sta = 3;
  		Error_Handler();
  	}

  	if ( HAL_FDCAN_Start(&hfdcan1) != HAL_OK)
  	{
  		sta = 3;
  		Error_Handler();
  	}
  	for (int i = 0; i < NUM_MOTORS; ++i)
	{
		// 모터를 Control Disable 모드로 전환
		if (HAL_FDCAN_GetTxFifoFreeLevel(&hfdcan1) > 0) {
			MIT_exit_control_mode(strawberry_robot.motors[i].id);
			strawberry_robot.motors[i].current_motor_mode = 0;
			//printf("Motor %d: Stopped and exited control mode.\r\n", strawberry_robot.motors[i].id);
		}
	}
  /* USER CODE END FDCAN1_Init 2 */

}

static void MX_USART3_UART_Init(void)
{

  huart3.Instance = USART3;
  huart3.Init.BaudRate = 921600;
  huart3.Init.WordLength = UART_WORDLENGTH_8B;
  huart3.Init.StopBits = UART_STOPBITS_1;
  huart3.Init.Parity = UART_PARITY_NONE;
  huart3.Init.Mode = UART_MODE_TX_RX;
  huart3.Init.HwFlowCtl = UART_HWCONTROL_NONE;
  huart3.Init.OverSampling = UART_OVERSAMPLING_16;
  huart3.Init.OneBitSampling = UART_ONE_BIT_SAMPLE_DISABLE;
  huart3.Init.ClockPrescaler = UART_PRESCALER_DIV1;
  huart3.AdvancedInit.AdvFeatureInit = UART_ADVFEATURE_NO_INIT;
  if (HAL_UART_Init(&huart3) != HAL_OK)
  {
    Error_Handler();
  }
  if (HAL_UARTEx_SetTxFifoThreshold(&huart3, UART_TXFIFO_THRESHOLD_1_2) != HAL_OK)
  {
    Error_Handler();
  }
  if (HAL_UARTEx_SetRxFifoThreshold(&huart3, UART_RXFIFO_THRESHOLD_1_2) != HAL_OK)
  {
    Error_Handler();
  }
  if (HAL_UARTEx_EnableFifoMode(&huart3) != HAL_OK)
  {
    Error_Handler();
  }

}

static void MX_DMA_Init(void)
{

  /* DMA controller clock enable */
  __HAL_RCC_DMA1_CLK_ENABLE();

  /* DMA interrupt init */
  /* DMA1_Stream0_IRQn interrupt configuration */
  HAL_NVIC_SetPriority(DMA1_Stream0_IRQn, 8, 0);
  HAL_NVIC_EnableIRQ(DMA1_Stream0_IRQn);
  /* DMA1_Stream1_IRQn interrupt configuration */
  HAL_NVIC_SetPriority(DMA1_Stream1_IRQn, 8, 0);
  HAL_NVIC_EnableIRQ(DMA1_Stream1_IRQn);
  /* DMAMUX1_OVR_IRQn interrupt configuration */
  HAL_NVIC_SetPriority(DMAMUX1_OVR_IRQn, 5, 0);
  HAL_NVIC_EnableIRQ(DMAMUX1_OVR_IRQn);

}

static void MX_GPIO_Init(void)
{
  GPIO_InitTypeDef GPIO_InitStruct = {0};

  /* GPIO Ports Clock Enable */
  __HAL_RCC_GPIOC_CLK_ENABLE();
  __HAL_RCC_GPIOH_CLK_ENABLE();
  __HAL_RCC_GPIOB_CLK_ENABLE();
  __HAL_RCC_GPIOD_CLK_ENABLE();
  __HAL_RCC_GPIOA_CLK_ENABLE();
  __HAL_RCC_GPIOE_CLK_ENABLE();

  /*Configure GPIO pin Output Level */
  HAL_GPIO_WritePin(GPIOB, GPIO_PIN_0|GPIO_PIN_14, GPIO_PIN_RESET);

  /*Configure GPIO pin Output Level */
  HAL_GPIO_WritePin(LD2_GPIO_Port, LD2_Pin, GPIO_PIN_RESET);

  /*Configure GPIO pin : PC13 */
  GPIO_InitStruct.Pin = GPIO_PIN_13;
  GPIO_InitStruct.Mode = GPIO_MODE_INPUT;
  GPIO_InitStruct.Pull = GPIO_NOPULL;
  HAL_GPIO_Init(GPIOC, &GPIO_InitStruct);

  /*Configure GPIO pins : PB0 PB14 */
  GPIO_InitStruct.Pin = GPIO_PIN_0|GPIO_PIN_14;
  GPIO_InitStruct.Mode = GPIO_MODE_OUTPUT_PP;
  GPIO_InitStruct.Pull = GPIO_NOPULL;
  GPIO_InitStruct.Speed = GPIO_SPEED_FREQ_LOW;
  HAL_GPIO_Init(GPIOB, &GPIO_InitStruct);

  /*Configure GPIO pin : LD2_Pin */
  GPIO_InitStruct.Pin = LD2_Pin;
  GPIO_InitStruct.Mode = GPIO_MODE_OUTPUT_PP;
  GPIO_InitStruct.Pull = GPIO_NOPULL;
  GPIO_InitStruct.Speed = GPIO_SPEED_FREQ_LOW;
  HAL_GPIO_Init(LD2_GPIO_Port, &GPIO_InitStruct);

}

void ControlTask(void *argument)
{
  /* USER CODE BEGIN 5 */
	// 1) 현재 커널 틱 수를 읽어와 기준 시점으로 저장
	TickType_t ctrl_tick_reference = xTaskGetTickCount();
	// 2) 2 ms 를 틱 단위로 환산하여 주기 변수에 저장
	const TickType_t ctrl_tick_period = pdMS_TO_TICKS(2);  // 2 ms
  /* Infinite loop */
	for (;;)
	{
		// 3) 2 ms 주기로 블록 → 이 시점이 매 2 ms마다 실행됨
		vTaskDelayUntil(&ctrl_tick_reference, ctrl_tick_period);

		// 4) 실제 경과 시간(틱)으로부터 ms 환산하여 누적
		// portTICK_PERIOD_MS 는 1 틱이 ms 단위로 몇 ms인지 정의 (보통 1)
		ctrl_time_ms_old = ctrl_time_ms;
		ctrl_time_ms += (ctrl_tick_period * portTICK_PERIOD_MS);

		// 5) LED1 토글: 주기가 잘 유지되는지 육안으로 확인
		HAL_GPIO_TogglePin(GPIOB, LED1_PIN);

		// 6) 여기서 PC로부터 들어온 task space PID Gain값과 Target Trajectory를 반영
		uart3_poll_and_process_lines();

		// 7) 현재 로봇이 Enable 상태인지, Disable 상태인지 판단
		if (strawberry_robot.current_robot_mode == 1) // Robot이 Enable 상태일 때
		{
			if (strawberry_robot.desired_robot_mode == 0) // Robot의 Disable 명령이 들어오면
			{
				for (int i = 0; i < NUM_MOTORS; ++i)
				{
					// 0. 로봇의 상태 전환 LED로 표시
					HAL_GPIO_TogglePin(GPIOB, LED2_PIN);
					// 1. 제어 입력 초기화
					strawberry_robot.motors[i].control_input = 0.0;
					if (HAL_FDCAN_GetTxFifoFreeLevel(&hfdcan1) > 0) {
						MIT_Mode(strawberry_robot.motors[i].id, strawberry_robot.motors[i].control_input);
					}
					// 2. 모터를 Control Disable 모드로 전환
					if (HAL_FDCAN_GetTxFifoFreeLevel(&hfdcan1) > 0) {
						MIT_exit_control_mode(strawberry_robot.motors[i].id);
						strawberry_robot.motors[i].current_motor_mode = 0;
						//printf("Motor %d: Stopped and exited control mode.\r\n", strawberry_robot.motors[i].id);
					}
				}
				// 3. 로봇의 상태를 Control Disable 상태로 초기화
				strawberry_robot.current_robot_mode = 0;
			}
			else // Robot의 Disable 명령이 들어오지 않으면
			{
				// 0. 각 IMU 값 센싱, 각 모터의 엔코더 값 센싱 및 모터 상태 업데이트
				for (int i = 0; i < NUM_IMUS; ++i)
				{
					link_IMU_read(&strawberry_robot.IMUs[i]);
				}
				for (int i = 0; i < NUM_MOTORS; ++i)
				{
					motor_encoder_read(&strawberry_robot.motors[i], 70.0);
				}
				// 1. 로봇의 상태 업데이트
				robot_state_update(&strawberry_robot);
				// 2. 로봇의 reference 업데이트
				set_trajectory(&strawberry_robot, &quintic_traj, taskTime, desired_posXYZ);
				get_target_point(&quintic_traj, target_posXYZ);
				// 3. 로봇의 Control Input 계산
				robot_pos_pid_gain_setting(&strawberry_robot, taskspace_p_gain, taskspace_d_gain, taskspace_i_gain, taskspace_windup_gain, taskspace_pid_cutoff);
				// target_posXYZ.pData[1] = homing_posXYZ.pData[1] + 0.2f * sinf(2.0f * pi * 1.0f * ((float32_t)ctrl_time_ms) / 1000.0f); // reference for gain tuning
				robot_pos_pid(&strawberry_robot, target_posXYZ);
				for (int i = 0; i < NUM_MOTORS; ++i)
				{
					//strawberry_robot.tau_bi.pData[i] = strawberry_robot.G_bi.pData[i];
					strawberry_robot.tau_bi.pData[i] = strawberry_robot.tau_bi.pData[i] + strawberry_robot.G_bi.pData[i];
					// 4. 로봇에서 계산한 Control Input을 모터 레벨로 내리기
					motor_feedforward_torque(&strawberry_robot.motors[i], strawberry_robot.tau_bi.pData[i] * strawberry_robot.axis_configuration[i]);
					// 5. CAN 통신 레지스터에 여유 슬롯이 있으면 현재 모터 제어값을 전송
					if (HAL_FDCAN_GetTxFifoFreeLevel(&hfdcan1) > 0) {
						//MIT_Mode(strawberry_robot.motors[i].id, 0.0f); // zero current for debugging
						MIT_Mode(strawberry_robot.motors[i].id, strawberry_robot.motors[i].control_input);
					}
				}
			}
		}
		else // Robot이 Disable 상태일 때
		{
			if (strawberry_robot.desired_robot_mode == 1) // Robot의 Enable 명령이 들어오면
			{
				for (int i = 0; i < NUM_IMUS; ++i)
				{
					// 1. CAN Rx 버퍼가 남아 있으면 모두 버림
					uint8_t dump[8];
					while (xQueueReceive(strawberry_robot.IMUs[i].canRxQueue_accel, dump, 0) == pdPASS) {
						/* drop */
					}
					while (xQueueReceive(strawberry_robot.IMUs[i].canRxQueue_gyro, dump, 0) == pdPASS) {
						/* drop */
					}
					// 2. 가속도 초기화
					strawberry_robot.IMUs[i].accelX = 0;
					strawberry_robot.IMUs[i].accelY = 0;
					strawberry_robot.IMUs[i].accelZ = 0;
					// 3. 각속도 초기화
					strawberry_robot.IMUs[i].gyroX = 0;
					strawberry_robot.IMUs[i].gyroY = 0;
					strawberry_robot.IMUs[i].gyroZ = 0;
				}
				for (int i = 0; i < NUM_MOTORS; ++i)
				{
					// 0. 로봇의 상태 전환 LED로 표시
					HAL_GPIO_TogglePin(GPIOB, LED2_PIN);
					ctrl_time_ms = 0;
					ctrl_time_ms_old = 0;
					// 1. 현재 위치 원점으로 초기화
					if (HAL_FDCAN_GetTxFifoFreeLevel(&hfdcan1) > 0) {
						MIT_reset_origin(strawberry_robot.motors[i].id);
					}
					// 2. CAN Rx 버퍼가 남아 있으면 모두 버림
					uint8_t dump[8];
					while (xQueueReceive(strawberry_robot.motors[i].canRxQueue, dump, 0) == pdPASS) {
						/* drop */
					}
					// 3. 모터를 Control Enable 모드로 전환
					if (HAL_FDCAN_GetTxFifoFreeLevel(&hfdcan1) > 0) {
						MIT_enter_control_mode(strawberry_robot.motors[i].id);
						strawberry_robot.motors[i].current_motor_mode = 1;
						//printf("Motor %d: Initialized and started.\r\n", strawberry_robot.motors[i].id);
					}
					// 4. 모터 제어 입력 초기화
					strawberry_robot.motors[i].control_input = 0.0;
					strawberry_robot.motors[i].control_input_old = 0.0;
					strawberry_robot.motors[i].control_input_excess = 0.0;
					// 5. 모터 엔코더 값 초기화
					strawberry_robot.motors[i].pos = 0.0;
					strawberry_robot.motors[i].pos_old = strawberry_robot.motors[i].pos;
					strawberry_robot.motors[i].vel = 0.0;
					strawberry_robot.motors[i].vel_old = strawberry_robot.motors[i].vel;
					// 6. 모터 Desired 값 초기 설정
					strawberry_robot.motors[i].pos_ref = target_pos[i];
					strawberry_robot.motors[i].vel_ref = target_vel[i];
					// 7. 모터 Position 제어 관련 오차 초기화
					strawberry_robot.motors[i].pos_error = strawberry_robot.motors[i].pos_ref - strawberry_robot.motors[i].pos;
					strawberry_robot.motors[i].pos_error_old = strawberry_robot.motors[i].pos_error;
					strawberry_robot.motors[i].pos_P_term = 0.0;
					strawberry_robot.motors[i].pos_I_term = 0.0;
					strawberry_robot.motors[i].pos_I_term_old = strawberry_robot.motors[i].pos_I_term;
					strawberry_robot.motors[i].pos_D_term = 0.0;
					strawberry_robot.motors[i].pos_D_term_old = strawberry_robot.motors[i].pos_D_term;
					// 8. 모터 Velocity 제어 관련 오차 초기화
					strawberry_robot.motors[i].vel_error = strawberry_robot.motors[i].vel_ref - strawberry_robot.motors[i].vel;
					strawberry_robot.motors[i].vel_error_old = strawberry_robot.motors[i].vel_error;
					strawberry_robot.motors[i].vel_P_term = 0.0;
					strawberry_robot.motors[i].vel_I_term = 0.0;
					strawberry_robot.motors[i].vel_I_term_old = strawberry_robot.motors[i].vel_I_term;
					// 9. 로봇 상태 값 초기화
					strawberry_robot.qdot_bi.pData[i] = 0.0;
					strawberry_robot.qddot_bi.pData[i] = 0.0;
					// 10. manipulator task space DOB control state 초기화
					strawberry_robot.DOB_lhs.pData[i] = 0.0;
					strawberry_robot.DOB_filtered_lhs.pData[i] = 0.0;
					strawberry_robot.DOB_rhs.pData[i] = 0.0;
					strawberry_robot.DOB_filtered_rhs.pData[i] = 0.0;
					// 11. manipulator control input 초기화
					strawberry_robot.tau_bi.pData[i] = 0.0;
					strawberry_robot.tau_bi_excess.pData[i] = 0.0;
				}
				for (int i = 0; i < NUM_TASK_DEG; ++i)
				{
					// 12. manipulator taskspace state 초기화
					strawberry_robot.posXYZ_ref.pData[i] = homing_posXYZ.pData[i];
					strawberry_robot.posXYZ.pData[i] = 0.0;
					strawberry_robot.velXYZ.pData[i] = 0.0;
					strawberry_robot.accXYZ.pData[i] = 0.0;

					// 13. manipulator task space pid control state 초기화
					strawberry_robot.pos_error.pData[i] = 0.0;
					strawberry_robot.pos_P_term.pData[i] = 0.0;
					strawberry_robot.pos_I_term.pData[i] = 0.0;
					strawberry_robot.pos_D_term.pData[i] = 0.0;
					strawberry_robot.pos_pid_output.pData[i] = 0.0;
					strawberry_robot.pos_pid_output_excess.pData[i] = 0.0;
					strawberry_robot.pos_pid_output_excess_old.pData[i] = 0.0;
				}
				for (int i=0;i<9;i++) strawberry_robot.M_bi_task.pData[i] = 0.0f;
				strawberry_robot.M_bi_task.pData[0]=1.0f;
				strawberry_robot.M_bi_task.pData[4]=1.0f;
				strawberry_robot.M_bi_task.pData[8]=1.0f;
				for (int i=0;i<9;i++) strawberry_robot.M_bi_task_nominal.pData[i] = 0.0f;
				strawberry_robot.M_bi_task_nominal.pData[0]=1.0f;
				strawberry_robot.M_bi_task_nominal.pData[4]=1.0f;
				strawberry_robot.M_bi_task_nominal.pData[8]=1.0f;
				// 14. 로봇의 남은 과거 상태 파라미터 초기화
				robot_state_update(&strawberry_robot);
				// 15. 로봇의 Trajectory 파라미터 초기화
				quintic_traj.initial_time = (float32_t) ctrl_time_ms / 1000.0f;
				quintic_traj.initial_pos[0] = homing_posXYZ.pData[0];
				quintic_traj.initial_pos[1] = homing_posXYZ.pData[1];
				quintic_traj.initial_pos[2] = homing_posXYZ.pData[2];
				quintic_traj.initial_vel[0] = 0.0f;
				quintic_traj.initial_vel[1] = 0.0f;
				quintic_traj.initial_vel[2] = 0.0f;
				quintic_traj.initial_acc[0] = 0.0f;
				quintic_traj.initial_acc[1] = 0.0f;
				quintic_traj.initial_acc[2] = 0.0f;
				set_trajectory(&strawberry_robot, &quintic_traj, taskTime, homing_posXYZ_buffer);
				get_target_point(&quintic_traj, target_posXYZ);
				// 16. 로봇의 상태를 Control Enable 상태로 초기화
				strawberry_robot.current_robot_mode = 1;
			}
		}
	}
  /* USER CODE END 5 */
}

void DataLoggingTask(void *argument)
{
  /* USER CODE BEGIN DataLoggingTask */
	// 1) 현재 커널 틱 수를 읽어와 기준 시점으로 저장
	TickType_t logging_tick_reference = xTaskGetTickCount();

	// 2) 2 ms 를 틱 단위로 환산하여 주기 변수에 저장
	const TickType_t logging_tick_period = pdMS_TO_TICKS(5);  // 5 ms

	  /* Infinite loop */
		for (;;)
		{
			// 3) 2 ms 주기로 블록 → 이 시점이 매 10 ms마다 실행됨
			vTaskDelayUntil(&logging_tick_reference, logging_tick_period);

			// 4) 실제 경과 시간(틱)으로부터 ms 환산하여 누적
			// portTICK_PERIOD_MS 는 1 틱이 ms 단위로 몇 ms인지 정의 (보통 1)
			logging_time_ms += (logging_tick_period * portTICK_PERIOD_MS);

			// 5) 현재 로봇의 상태를 Serial 통신을 통해 PC로 전송
			if (strawberry_robot.current_robot_mode == 1) // 로봇의 현재 상태가 Control Enable인 경우
			{
				printf("[%.3f, %d, %d, %.3f, %d, %.3f, %d, %.3f, %.3f, %.3f, %.3f, %.3f, %.3f, %.3f, %.3f, %.3f, %.3f, %.3f, %.3f, %.3f]\r\n",
						(float32_t) ctrl_time_ms/1000, strawberry_robot.current_robot_mode,
						strawberry_robot.motors[0].current_motor_mode, strawberry_robot.motors[0].control_input * strawberry_robot.axis_configuration[0],
						strawberry_robot.motors[1].current_motor_mode, strawberry_robot.motors[1].control_input * strawberry_robot.axis_configuration[1],
						strawberry_robot.motors[2].current_motor_mode, strawberry_robot.motors[2].control_input * strawberry_robot.axis_configuration[2],
						strawberry_robot.q_bi.pData[0], strawberry_robot.q_bi.pData[1], strawberry_robot.q_bi.pData[2],
						strawberry_robot.posXYZ_ref.pData[0], strawberry_robot.posXYZ_ref.pData[1], strawberry_robot.posXYZ_ref.pData[2],
						strawberry_robot.posXYZ.pData[0], strawberry_robot.posXYZ.pData[1], strawberry_robot.posXYZ.pData[2],
						strawberry_robot.pos_I_term.pData[0], strawberry_robot.pos_I_term.pData[1], strawberry_robot.pos_I_term.pData[2]);
			}
			else // 로봇의 현재 상태가 Control Disable인 경우
			{
				printf("[%.3f, %d, %d, %.3f, %d, %.3f, %d, %.3f, %.3f, %.3f, %.3f, %.3f, %.3f, %.3f, %.3f, %.3f, %.3f, %.3f, %.3f, %.3f]\r\n",
						(float32_t) ctrl_time_ms/1000, strawberry_robot.current_robot_mode,
						strawberry_robot.motors[0].current_motor_mode, strawberry_robot.motors[0].control_input * strawberry_robot.axis_configuration[0],
						strawberry_robot.motors[1].current_motor_mode, strawberry_robot.motors[1].control_input * strawberry_robot.axis_configuration[1],
						strawberry_robot.motors[2].current_motor_mode, strawberry_robot.motors[2].control_input * strawberry_robot.axis_configuration[2],
						strawberry_robot.q_bi.pData[0], strawberry_robot.q_bi.pData[1], strawberry_robot.q_bi.pData[2],
						strawberry_robot.posXYZ_ref.pData[0], strawberry_robot.posXYZ_ref.pData[1], strawberry_robot.posXYZ_ref.pData[2],
						strawberry_robot.posXYZ.pData[0], strawberry_robot.posXYZ.pData[1], strawberry_robot.posXYZ.pData[2],
						strawberry_robot.pos_I_term.pData[0], strawberry_robot.pos_I_term.pData[1], strawberry_robot.pos_I_term.pData[2]);
			}
		}
  /* USER CODE END DataLoggingTask */
}

 /* MPU Configuration */

void MPU_Config(void)
{
  MPU_Region_InitTypeDef MPU_InitStruct = {0};

  /* Disables the MPU */
  HAL_MPU_Disable();

  /** Initializes and configures the Region and the memory to be protected
  */
  MPU_InitStruct.Enable = MPU_REGION_ENABLE;
  MPU_InitStruct.Number = MPU_REGION_NUMBER0;
  MPU_InitStruct.BaseAddress = 0x0;
  MPU_InitStruct.Size = MPU_REGION_SIZE_4GB;
  MPU_InitStruct.SubRegionDisable = 0x87;
  MPU_InitStruct.TypeExtField = MPU_TEX_LEVEL0;
  MPU_InitStruct.AccessPermission = MPU_REGION_NO_ACCESS;
  MPU_InitStruct.DisableExec = MPU_INSTRUCTION_ACCESS_DISABLE;
  MPU_InitStruct.IsShareable = MPU_ACCESS_SHAREABLE;
  MPU_InitStruct.IsCacheable = MPU_ACCESS_NOT_CACHEABLE;
  MPU_InitStruct.IsBufferable = MPU_ACCESS_NOT_BUFFERABLE;

  HAL_MPU_ConfigRegion(&MPU_InitStruct);
  /* Enables the MPU */
  HAL_MPU_Enable(MPU_PRIVILEGED_DEFAULT);

}

void HAL_TIM_PeriodElapsedCallback(TIM_HandleTypeDef *htim)
{
  if (htim->Instance == TIM7)
  {
    HAL_IncTick();
  }
}

void Error_Handler(void)
{
  /* USER CODE BEGIN Error_Handler_Debug */
  /* User can add his own implementation to report the HAL error return state */
	if (strawberry_robot.current_robot_mode == 1)
  	{
  		for (int i = 0; i < NUM_MOTORS; ++i)
  		{
  			HAL_GPIO_TogglePin(GPIOB, LED2_PIN);
  			// 제어 입력 초기화
  			strawberry_robot.motors[i].control_input = 0.0;
			if (HAL_FDCAN_GetTxFifoFreeLevel(&hfdcan1) > 0) {
				MIT_Mode (strawberry_robot.motors[i].id, strawberry_robot.motors[i].control_input);
			}
			if (HAL_FDCAN_GetTxFifoFreeLevel(&hfdcan1) > 0) {
				MIT_exit_control_mode(strawberry_robot.motors[i].id);
			}
			//printf("Motor %d: Stopped and exited control mode.\r\n", strawberry_robot.motors[i].id);
  		}
		strawberry_robot.current_robot_mode = 0;
  	}
	switch(sta) {
	  case 1: printf("Error Code: %d, This is CAN Tx Error.\r\n", sta); break;
	  case 2: printf("Error Code: %d, This is CAN Rx Error.\r\n", sta); break;
	  case 3: printf("Error Code: %d, This is MCU Initialization Error.\r\n", sta); break;
	  case 4: printf("Error Code: %d, This is Matrix Calculation Error.\r\n", sta); break;
	  case 5: printf("Error Code: %d, This is Range of Motion Error.\r\n", sta); break;
	  default: printf("Error Code: Unknown");
	}
  while (1)
  {
	  for (int i = 0; i < sta; i++) {
	      HAL_GPIO_TogglePin(GPIOB, LED3_PIN);  // LED 반전
	      HAL_Delay(200);                       // 200ms 간격 (필요시 조절)
	      HAL_GPIO_TogglePin(GPIOB, LED3_PIN);  // LED 원래 상태 복귀
	      HAL_Delay(200);
	  }
	  HAL_Delay(1000);
  }
  /* USER CODE END Error_Handler_Debug */
}
